AUTOSAR XML (schema 4-3-0)
standard types defined: SInt32, UInt16, UInt32, UInt8, sint32, uint16, uint32, uint8
package /DataTypes
  impl type SGaugeInfo_u32dyn_3: category=ARRAY, sw-calibration-access=READ-ONLY, type-emitter=RTE
    element Element: array-size=3, array-size-semantics=FIXED-SIZE, implementation-data-type=SGaugeInfo_u32dyn
package /E40_Platform_System_SystemPackage/Components
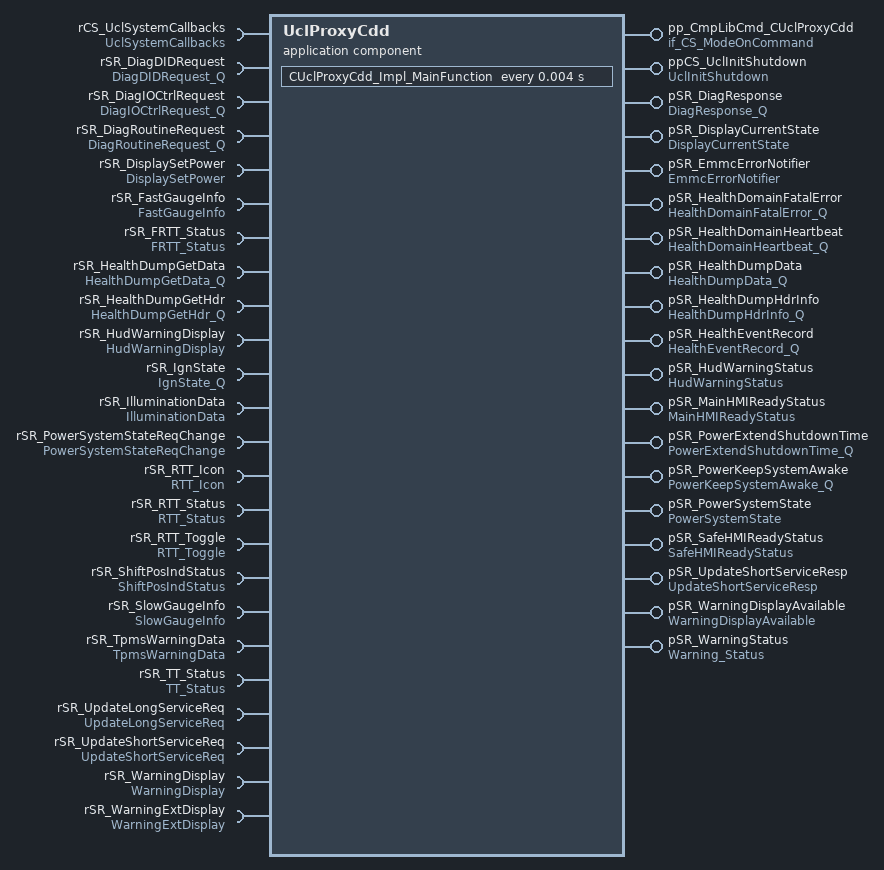
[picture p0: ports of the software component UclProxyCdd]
  application sw component type UclProxyCdd
    19 x provide port:
      pp_CmpLibCmd_CUclProxyCdd: server-com-spec{operation=Impl_OnCommand, queue-length=1}, provided-interface=if_CS_ModeOnCommand
      ppCS_UclInitShutdown: provided-com-specs=[{operation=Impl_Initialize, queue-length=1}, {operation=Impl_Shutdown, queue-length=1}], provided-interface=UclInitShutdown
      pSR_DiagResponse: queued-sender-com-spec=data-element=DiagResponseData, provided-interface=DiagResponse_Q
      pSR_DisplayCurrentState: nonqueued-sender-com-spec{data-element=DisplayCurrentStateData, init-value=constant-reference=UclProxyCddDisplayCurrentStateDataValue0}, provided-interface=DisplayCurrentState
      pSR_EmmcErrorNotifier: nonqueued-sender-com-spec{data-element=EmmcErrorNotifierData, init-value=constant-reference=UclProxyCddEmmcErrorNotifierDataValue0}, provided-interface=EmmcErrorNotifier
      pSR_HealthDomainFatalError: queued-sender-com-spec=data-element=HealthDomainFatalErrorData, provided-interface=HealthDomainFatalError_Q
      pSR_HealthDomainHeartbeat: queued-sender-com-spec=data-element=HealthDomainHeartbeatData, provided-interface=HealthDomainHeartbeat_Q
      pSR_HealthDumpData: queued-sender-com-spec=data-element=HealthDumpDataData, provided-interface=HealthDumpData_Q
      pSR_HealthDumpHdrInfo: queued-sender-com-spec=data-element=HealthDumpHdrInfoData, provided-interface=HealthDumpHdrInfo_Q
      pSR_HealthEventRecord: queued-sender-com-spec=data-element=HealthEventRecordData, provided-interface=HealthEventRecord_Q
      pSR_HudWarningStatus: nonqueued-sender-com-spec{data-element=HudWarningStatusData, init-value=constant-reference=UclProxyCddHudWarningStatusDataValue0}, provided-interface=HudWarningStatus
      pSR_MainHMIReadyStatus: queued-sender-com-spec=data-element=MainHMIReadyStatusData, provided-interface=MainHMIReadyStatus
      pSR_PowerExtendShutdownTime: queued-sender-com-spec=data-element=PowerExtendShutdownTimeData, provided-interface=PowerExtendShutdownTime_Q
      pSR_PowerKeepSystemAwake: queued-sender-com-spec=data-element=PowerKeepSystemAwakeData, provided-interface=PowerKeepSystemAwake_Q
      pSR_PowerSystemState: nonqueued-sender-com-spec{data-element=PowerSystemStateData, init-value=constant-reference=UclProxyCddPowerSystemStateDataValue0}, provided-interface=PowerSystemState
      pSR_SafeHMIReadyStatus: queued-sender-com-spec=data-element=SafeHMIReadyStatusData, provided-interface=SafeHMIReadyStatus
      pSR_UpdateShortServiceResp: queued-sender-com-spec=data-element=UpdateShortServiceRespData, provided-interface=UpdateShortServiceResp
      pSR_WarningDisplayAvailable: nonqueued-sender-com-spec{data-element=WarningDisplayAvailableData, init-value=constant-reference=UclProxyCddWarningDisplayAvailableDataValue0}, provided-interface=WarningDisplayAvailable
      pSR_WarningStatus: nonqueued-sender-com-spec{data-element=WarningStatusData, init-value=constant-reference=UclProxyCddWarningStatusDataValue0}, provided-interface=Warning_Status
    24 x require port:
      rCS_UclSystemCallbacks: required-com-specs=[ErrorNotification, LinkStatusChanged], required-interface=UclSystemCallbacks
      rSR_DiagDIDRequest: queued-receiver-com-spec{data-element=DiagDIDRequestData, queue-length=2}, required-interface=DiagDIDRequest_Q
      rSR_DiagIOCtrlRequest: queued-receiver-com-spec{data-element=DiagIOCtrlRequestData, queue-length=2}, required-interface=DiagIOCtrlRequest_Q
      rSR_DiagRoutineRequest: queued-receiver-com-spec{data-element=DiagRoutineRequestData, queue-length=2}, required-interface=DiagRoutineRequest_Q
      rSR_DisplaySetPower: nonqueued-receiver-com-spec{data-element=DisplaySetPowerData, filter=data-filter-type=ALWAYS, init-value=constant-reference=UclProxyCddDisplaySetPowerDataValue0}, required-interface=DisplaySetPower
      rSR_FastGaugeInfo: nonqueued-receiver-com-spec{data-element=FastGaugeInfoData, filter=data-filter-type=ALWAYS, init-value=constant-reference=UclProxyCddFastGaugeInfoDataValue0}, required-interface=FastGaugeInfo
      rSR_FRTT_Status: nonqueued-receiver-com-spec{data-element=FRTT_StatusData, filter=data-filter-type=ALWAYS, init-value=constant-reference=UclProxyCddFRTT_StatusDataValue0}, required-interface=FRTT_Status
      rSR_HealthDumpGetData: queued-receiver-com-spec{data-element=HealthDumpGetDataData, queue-length=1}, required-interface=HealthDumpGetData_Q
      rSR_HealthDumpGetHdr: queued-receiver-com-spec{data-element=HealthDumpGetHdrData, queue-length=1}, required-interface=HealthDumpGetHdr_Q
      rSR_HudWarningDisplay: nonqueued-receiver-com-spec{data-element=HudWarningDisplayData, filter=data-filter-type=ALWAYS, init-value=constant-reference=UclProxyCddHudWarningDisplayDataValue0}, required-interface=HudWarningDisplay
      rSR_IgnState: queued-receiver-com-spec{data-element=IgnStateData, queue-length=5}, required-interface=IgnState_Q
      rSR_IlluminationData: nonqueued-receiver-com-spec{data-element=IlluminationDataData, filter=data-filter-type=ALWAYS, init-value=constant-reference=UclProxyCddIlluminationDataDataValue0}, required-interface=IlluminationData
      rSR_PowerSystemStateReqChange: nonqueued-receiver-com-spec{data-element=PowerSystemStateReqChangeData, filter=data-filter-type=ALWAYS, init-value=constant-reference=UclProxyCddPowerSystemStateReqChangeDataValue0}, required-interface=PowerSystemStateReqChange
      rSR_RTT_Icon: nonqueued-receiver-com-spec{data-element=RTT_IconData, filter=data-filter-type=ALWAYS, init-value=constant-reference=UclProxyCddRTT_IconDataValue0}, required-interface=RTT_Icon
      rSR_RTT_Status: nonqueued-receiver-com-spec{data-element=RTT_StatusData, filter=data-filter-type=ALWAYS, init-value=constant-reference=UclProxyCddRTT_StatusDataValue0}, required-interface=RTT_Status
      rSR_RTT_Toggle: nonqueued-receiver-com-spec{data-element=RTT_ToggleData, filter=data-filter-type=ALWAYS, init-value=constant-reference=UclProxyCddRTT_ToggleDataValue0}, required-interface=RTT_Toggle
      rSR_ShiftPosIndStatus: nonqueued-receiver-com-spec{data-element=ShiftPosIndStatusData, filter=data-filter-type=ALWAYS, init-value=constant-reference=UclProxyCddShiftPosIndStatusDataValue0}, required-interface=ShiftPosIndStatus
      rSR_SlowGaugeInfo: nonqueued-receiver-com-spec{data-element=SlowGaugeInfoData, filter=data-filter-type=ALWAYS, init-value=constant-reference=UclProxyCddSlowGaugeInfoDataValue0}, required-interface=SlowGaugeInfo
      rSR_TpmsWarningData: nonqueued-receiver-com-spec{data-element=TpmsWarningDataData, filter=data-filter-type=ALWAYS, init-value=constant-reference=UclProxyCddTpmsWarningDataDataValue0}, required-interface=TpmsWarningData
      rSR_TT_Status: nonqueued-receiver-com-spec{data-element=TT_StatusData, filter=data-filter-type=ALWAYS, init-value=constant-reference=UclProxyCddTT_StatusDataValue0}, required-interface=TT_Status
      rSR_UpdateLongServiceReq: queued-receiver-com-spec{data-element=UpdateLongServiceReqData, queue-length=1}, required-interface=UpdateLongServiceReq
      rSR_UpdateShortServiceReq: queued-receiver-com-spec{data-element=UpdateShortServiceReqData, queue-length=1}, required-interface=UpdateShortServiceReq
      rSR_WarningDisplay: nonqueued-receiver-com-spec{data-element=WarningDisplayData, filter=data-filter-type=ALWAYS, init-value=constant-reference=UclProxyCddWarningDisplayDataValue0}, required-interface=WarningDisplay
      rSR_WarningExtDisplay: nonqueued-receiver-com-spec{data-element=WarningExtDisplayData, filter=data-filter-type=ALWAYS, init-value=constant-reference=UclProxyCddWarningExtDisplayDataValue0}, required-interface=WarningExtDisplay
    behavior IB_UclProxyCdd
      operation invoked event OIE_ppCS_UclInitShutdown_CUclProxyCdd_Impl_InitializeTrigByImpl_Initialize: start-on-event=CUclProxyCdd_Impl_Initialize, operation=ppCS_UclInitShutdown.Impl_Initialize
      timing event TECUclProxyCdd_Impl_MainFunction: start-on-event=CUclProxyCdd_Impl_MainFunction, period=0.004
      operation invoked event OIE_pp_CmpLibCmd_CUclProxyCdd_CUclProxyCdd_Impl_OnCommandTrigByImpl_OnCommand: start-on-event=CUclProxyCdd_Impl_OnCommand, operation=pp_CmpLibCmd_CUclProxyCdd.Impl_OnCommand
      operation invoked event OIE_ppCS_UclInitShutdown_CUclProxyCdd_Impl_ShutdownTrigByImpl_Shutdown: start-on-event=CUclProxyCdd_Impl_Shutdown, operation=ppCS_UclInitShutdown.Impl_Shutdown
      20 x data received event:
        DREOnDre_DiagDIDRequestTrigByDiagDIDRequestData: start-on-event=OnDre_DiagDIDRequest, data=rSR_DiagDIDRequest.DiagDIDRequestData
        DREOnDre_DiagIOCtrlRequestTrigByDiagIOCtrlRequestData: start-on-event=OnDre_DiagIOCtrlRequest, data=rSR_DiagIOCtrlRequest.DiagIOCtrlRequestData
        DREOnDre_DiagRoutineRequestTrigByDiagRoutineRequestData: start-on-event=OnDre_DiagRoutineRequest, data=rSR_DiagRoutineRequest.DiagRoutineRequestData
        DREOnDre_DisplaySetPowerTrigByDisplaySetPowerData: start-on-event=OnDre_DisplaySetPower, data=rSR_DisplaySetPower.DisplaySetPowerData
        DREOnDre_FastGaugeInfoTrigByFastGaugeInfoData: start-on-event=OnDre_FastGaugeInfo, data=rSR_FastGaugeInfo.FastGaugeInfoData
        DREOnDre_FRTT_StatusTrigByFRTT_StatusData: start-on-event=OnDre_FRTT_Status, data=rSR_FRTT_Status.FRTT_StatusData
        DREOnDre_HealthDumpGetDataTrigByHealthDumpGetDataData: start-on-event=OnDre_HealthDumpGetData, data=rSR_HealthDumpGetData.HealthDumpGetDataData
        DREOnDre_HealthDumpGetHdrTrigByHealthDumpGetHdrData: start-on-event=OnDre_HealthDumpGetHdr, data=rSR_HealthDumpGetHdr.HealthDumpGetHdrData
        DREOnDre_IlluminationDataTrigByIlluminationDataData: start-on-event=OnDre_IlluminationData, data=rSR_IlluminationData.IlluminationDataData
        DREOnDre_PowerSystemStateReqChangeTrigByPowerSystemStateReqChangeData: start-on-event=OnDre_PowerSystemStateReqChange, data=rSR_PowerSystemStateReqChange.PowerSystemStateReqChangeData
        DREOnDre_RTT_IconTrigByRTT_IconData: start-on-event=OnDre_RTT_Icon, data=rSR_RTT_Icon.RTT_IconData
        DREOnDre_RTT_StatusTrigByRTT_StatusData: start-on-event=OnDre_RTT_Status, data=rSR_RTT_Status.RTT_StatusData
        DREOnDre_RTT_ToggleTrigByRTT_ToggleData: start-on-event=OnDre_RTT_Toggle, data=rSR_RTT_Toggle.RTT_ToggleData
        DREOnDre_ShiftPosIndStatusTrigByShiftPosIndStatusData: start-on-event=OnDre_ShiftPosIndStatus, data=rSR_ShiftPosIndStatus.ShiftPosIndStatusData
        DREOnDre_SlowGaugeInfoTrigBySlowGaugeInfoData: start-on-event=OnDre_SlowGaugeInfo, data=rSR_SlowGaugeInfo.SlowGaugeInfoData
        DREOnDre_TT_StatusTrigByTT_StatusData: start-on-event=OnDre_TT_Status, data=rSR_TT_Status.TT_StatusData
        DREOnDre_UpdateLongServiceReqTrigByUpdateLongServiceReqData: start-on-event=OnDre_UpdateLongServiceReq, data=rSR_UpdateLongServiceReq.UpdateLongServiceReqData
        DREOnDre_UpdateShortServiceReqTrigByUpdateShortServiceReqData: start-on-event=OnDre_UpdateShortServiceReq, data=rSR_UpdateShortServiceReq.UpdateShortServiceReqData
        DREOnDre_WarningDisplayTrigByWarningDisplayData: start-on-event=OnDre_WarningDisplay, data=rSR_WarningDisplay.WarningDisplayData
        DREOnDre_WarningExtDisplayTrigByWarningExtDisplayData: start-on-event=OnDre_WarningExtDisplay, data=rSR_WarningExtDisplay.WarningExtDisplayData
      port-api-options:
        enable-take-address=false, error-handling=NO-TRANSFORMER-ERROR-HANDLING, indirect-api=false, port=pp_CmpLibCmd_CUclProxyCdd
        enable-take-address=false, error-handling=NO-TRANSFORMER-ERROR-HANDLING, indirect-api=false, port=ppCS_UclInitShutdown
        enable-take-address=false, error-handling=NO-TRANSFORMER-ERROR-HANDLING, indirect-api=false, port=pSR_DiagResponse
        enable-take-address=false, error-handling=NO-TRANSFORMER-ERROR-HANDLING, indirect-api=false, port=pSR_DisplayCurrentState
        enable-take-address=false, error-handling=NO-TRANSFORMER-ERROR-HANDLING, indirect-api=false, port=pSR_EmmcErrorNotifier
        enable-take-address=false, error-handling=NO-TRANSFORMER-ERROR-HANDLING, indirect-api=false, port=pSR_HealthDomainFatalError
        enable-take-address=false, error-handling=NO-TRANSFORMER-ERROR-HANDLING, indirect-api=false, port=pSR_HealthDomainHeartbeat
        enable-take-address=false, error-handling=NO-TRANSFORMER-ERROR-HANDLING, indirect-api=false, port=pSR_HealthDumpData
        enable-take-address=false, error-handling=NO-TRANSFORMER-ERROR-HANDLING, indirect-api=false, port=pSR_HealthDumpHdrInfo
        enable-take-address=false, error-handling=NO-TRANSFORMER-ERROR-HANDLING, indirect-api=false, port=pSR_HealthEventRecord
        enable-take-address=false, error-handling=NO-TRANSFORMER-ERROR-HANDLING, indirect-api=false, port=pSR_HudWarningStatus
        enable-take-address=false, error-handling=NO-TRANSFORMER-ERROR-HANDLING, indirect-api=false, port=pSR_MainHMIReadyStatus
        enable-take-address=false, error-handling=NO-TRANSFORMER-ERROR-HANDLING, indirect-api=false, port=pSR_PowerExtendShutdownTime
        enable-take-address=false, error-handling=NO-TRANSFORMER-ERROR-HANDLING, indirect-api=false, port=pSR_PowerKeepSystemAwake
        enable-take-address=false, error-handling=NO-TRANSFORMER-ERROR-HANDLING, indirect-api=false, port=pSR_PowerSystemState
        enable-take-address=false, error-handling=NO-TRANSFORMER-ERROR-HANDLING, indirect-api=false, port=pSR_SafeHMIReadyStatus
        enable-take-address=false, error-handling=NO-TRANSFORMER-ERROR-HANDLING, indirect-api=false, port=pSR_UpdateShortServiceResp
        enable-take-address=false, error-handling=NO-TRANSFORMER-ERROR-HANDLING, indirect-api=false, port=pSR_WarningDisplayAvailable
        enable-take-address=false, error-handling=NO-TRANSFORMER-ERROR-HANDLING, indirect-api=false, port=pSR_WarningStatus
        enable-take-address=false, error-handling=NO-TRANSFORMER-ERROR-HANDLING, indirect-api=false, port=rCS_UclSystemCallbacks
        enable-take-address=false, error-handling=NO-TRANSFORMER-ERROR-HANDLING, indirect-api=false, port=rSR_DiagDIDRequest
        enable-take-address=false, error-handling=NO-TRANSFORMER-ERROR-HANDLING, indirect-api=false, port=rSR_DiagIOCtrlRequest
        enable-take-address=false, error-handling=NO-TRANSFORMER-ERROR-HANDLING, indirect-api=false, port=rSR_DiagRoutineRequest
        enable-take-address=false, error-handling=NO-TRANSFORMER-ERROR-HANDLING, indirect-api=false, port=rSR_DisplaySetPower
        enable-take-address=false, error-handling=NO-TRANSFORMER-ERROR-HANDLING, indirect-api=false, port=rSR_FastGaugeInfo
        enable-take-address=false, error-handling=NO-TRANSFORMER-ERROR-HANDLING, indirect-api=false, port=rSR_FRTT_Status
        enable-take-address=false, error-handling=NO-TRANSFORMER-ERROR-HANDLING, indirect-api=false, port=rSR_HealthDumpGetData
        enable-take-address=false, error-handling=NO-TRANSFORMER-ERROR-HANDLING, indirect-api=false, port=rSR_HealthDumpGetHdr
        enable-take-address=false, error-handling=NO-TRANSFORMER-ERROR-HANDLING, indirect-api=false, port=rSR_HudWarningDisplay
        enable-take-address=false, error-handling=NO-TRANSFORMER-ERROR-HANDLING, indirect-api=false, port=rSR_IgnState
        enable-take-address=false, error-handling=NO-TRANSFORMER-ERROR-HANDLING, indirect-api=false, port=rSR_IlluminationData
        enable-take-address=false, error-handling=NO-TRANSFORMER-ERROR-HANDLING, indirect-api=false, port=rSR_PowerSystemStateReqChange
        enable-take-address=false, error-handling=NO-TRANSFORMER-ERROR-HANDLING, indirect-api=false, port=rSR_RTT_Icon
        enable-take-address=false, error-handling=NO-TRANSFORMER-ERROR-HANDLING, indirect-api=false, port=rSR_RTT_Status
        enable-take-address=false, error-handling=NO-TRANSFORMER-ERROR-HANDLING, indirect-api=false, port=rSR_RTT_Toggle
        enable-take-address=false, error-handling=NO-TRANSFORMER-ERROR-HANDLING, indirect-api=false, port=rSR_ShiftPosIndStatus
        enable-take-address=false, error-handling=NO-TRANSFORMER-ERROR-HANDLING, indirect-api=false, port=rSR_SlowGaugeInfo
        enable-take-address=false, error-handling=NO-TRANSFORMER-ERROR-HANDLING, indirect-api=false, port=rSR_TpmsWarningData
        enable-take-address=false, error-handling=NO-TRANSFORMER-ERROR-HANDLING, indirect-api=false, port=rSR_TT_Status
        enable-take-address=false, error-handling=NO-TRANSFORMER-ERROR-HANDLING, indirect-api=false, port=rSR_UpdateLongServiceReq
        enable-take-address=false, error-handling=NO-TRANSFORMER-ERROR-HANDLING, indirect-api=false, port=rSR_UpdateShortServiceReq
        enable-take-address=false, error-handling=NO-TRANSFORMER-ERROR-HANDLING, indirect-api=false, port=rSR_WarningDisplay
        enable-take-address=false, error-handling=NO-TRANSFORMER-ERROR-HANDLING, indirect-api=false, port=rSR_WarningExtDisplay
      24 x runnable, all with can-be-invoked-concurrently=true:
        CUclProxyCdd_Impl_Initialize
        CUclProxyCdd_Impl_MainFunction
          data-receive-point-by-arguments:
            23 x access:
              DRA_rSR_DisplaySetPower_DisplaySetPowerData: accessed-variable=rSR_DisplaySetPower.DisplaySetPowerData
              DRA_rSR_FastGaugeInfo_FastGaugeInfoData: accessed-variable=rSR_FastGaugeInfo.FastGaugeInfoData
              DRA_rSR_FRTT_Status_FRTT_StatusData: accessed-variable=rSR_FRTT_Status.FRTT_StatusData
              DRA_rSR_HudWarningDisplay_HudWarningDisplayData: accessed-variable=rSR_HudWarningDisplay.HudWarningDisplayData
              DRA_rSR_IlluminationData_IlluminationDataData: accessed-variable=rSR_IlluminationData.IlluminationDataData
              DRA_rSR_PowerSystemStateReqChange_PowerSystemStateReqChangeData: accessed-variable=rSR_PowerSystemStateReqChange.PowerSystemStateReqChangeData
              DRA_rSR_RTT_Icon_RTT_IconData: accessed-variable=rSR_RTT_Icon.RTT_IconData
              DRA_rSR_RTT_Status_RTT_StatusData: accessed-variable=rSR_RTT_Status.RTT_StatusData
              DRA_rSR_RTT_Toggle_RTT_ToggleData: accessed-variable=rSR_RTT_Toggle.RTT_ToggleData
              DRA_rSR_ShiftPosIndStatus_ShiftPosIndStatusData: accessed-variable=rSR_ShiftPosIndStatus.ShiftPosIndStatusData
              DRA_rSR_SlowGaugeInfo_SlowGaugeInfoData: accessed-variable=rSR_SlowGaugeInfo.SlowGaugeInfoData
              DRA_rSR_TpmsWarningData_TpmsWarningDataData: accessed-variable=rSR_TpmsWarningData.TpmsWarningDataData
              DRA_rSR_TT_Status_TT_StatusData: accessed-variable=rSR_TT_Status.TT_StatusData
              DRA_rSR_WarningDisplay_WarningDisplayData: accessed-variable=rSR_WarningDisplay.WarningDisplayData
              DRA_rSR_WarningExtDisplay_WarningExtDisplayData: accessed-variable=rSR_WarningExtDisplay.WarningExtDisplayData
              DRP_rSR_DiagDIDRequest_DiagDIDRequestData: accessed-variable=rSR_DiagDIDRequest.DiagDIDRequestData
              DRP_rSR_DiagIOCtrlRequest_DiagIOCtrlRequestData: accessed-variable=rSR_DiagIOCtrlRequest.DiagIOCtrlRequestData
              DRP_rSR_DiagRoutineRequest_DiagRoutineRequestData: accessed-variable=rSR_DiagRoutineRequest.DiagRoutineRequestData
              DRP_rSR_HealthDumpGetData_HealthDumpGetDataData: accessed-variable=rSR_HealthDumpGetData.HealthDumpGetDataData
              DRP_rSR_HealthDumpGetHdr_HealthDumpGetHdrData: accessed-variable=rSR_HealthDumpGetHdr.HealthDumpGetHdrData
              DRP_rSR_IgnState_IgnStateData: accessed-variable=rSR_IgnState.IgnStateData
              DRP_rSR_UpdateLongServiceReq_UpdateLongServiceReqData: accessed-variable=rSR_UpdateLongServiceReq.UpdateLongServiceReqData
              DRP_rSR_UpdateShortServiceReq_UpdateShortServiceReqData: accessed-variable=rSR_UpdateShortServiceReq.UpdateShortServiceReqData
          data-send-points:
            17 x access:
              DSP_pSR_DiagResponse_DiagResponseData: accessed-variable=pSR_DiagResponse.DiagResponseData
              DSP_pSR_HealthDomainFatalError_HealthDomainFatalErrorData: accessed-variable=pSR_HealthDomainFatalError.HealthDomainFatalErrorData
              DSP_pSR_HealthDomainHeartbeat_HealthDomainHeartbeatData: accessed-variable=pSR_HealthDomainHeartbeat.HealthDomainHeartbeatData
              DSP_pSR_HealthDumpData_HealthDumpDataData: accessed-variable=pSR_HealthDumpData.HealthDumpDataData
              DSP_pSR_HealthDumpHdrInfo_HealthDumpHdrInfoData: accessed-variable=pSR_HealthDumpHdrInfo.HealthDumpHdrInfoData
              DSP_pSR_HealthEventRecord_HealthEventRecordData: accessed-variable=pSR_HealthEventRecord.HealthEventRecordData
              DSP_pSR_MainHMIReadyStatus_MainHMIReadyStatusData: accessed-variable=pSR_MainHMIReadyStatus.MainHMIReadyStatusData
              DSP_pSR_PowerExtendShutdownTime_PowerExtendShutdownTimeData: accessed-variable=pSR_PowerExtendShutdownTime.PowerExtendShutdownTimeData
              DSP_pSR_PowerKeepSystemAwake_PowerKeepSystemAwakeData: accessed-variable=pSR_PowerKeepSystemAwake.PowerKeepSystemAwakeData
              DSP_pSR_SafeHMIReadyStatus_SafeHMIReadyStatusData: accessed-variable=pSR_SafeHMIReadyStatus.SafeHMIReadyStatusData
              DSP_pSR_UpdateShortServiceResp_UpdateShortServiceRespData: accessed-variable=pSR_UpdateShortServiceResp.UpdateShortServiceRespData
              DWA_pSR_DisplayCurrentState_DisplayCurrentStateData: accessed-variable=pSR_DisplayCurrentState.DisplayCurrentStateData
              DWA_pSR_EmmcErrorNotifier_EmmcErrorNotifierData: accessed-variable=pSR_EmmcErrorNotifier.EmmcErrorNotifierData
              DWA_pSR_HudWarningStatus_HudWarningStatusData: accessed-variable=pSR_HudWarningStatus.HudWarningStatusData
              DWA_pSR_PowerSystemState_PowerSystemStateData: accessed-variable=pSR_PowerSystemState.PowerSystemStateData
              DWA_pSR_WarningDisplayAvailable_WarningDisplayAvailableData: accessed-variable=pSR_WarningDisplayAvailable.WarningDisplayAvailableData
              DWA_pSR_WarningStatus_WarningStatusData: accessed-variable=pSR_WarningStatus.WarningStatusData
          sync call OA_rCS_UclSystemCallbacks_ErrorNotification: operation=rCS_UclSystemCallbacks.ErrorNotification, timeout=0
          sync call OA_rCS_UclSystemCallbacks_LinkStatusChanged: operation=rCS_UclSystemCallbacks.LinkStatusChanged, timeout=0
        CUclProxyCdd_Impl_OnCommand
        CUclProxyCdd_Impl_Shutdown
        OnDre_DiagDIDRequest
          data-receive-point-by-arguments:
            23 x access:
              DRA_rSR_DisplaySetPower_DisplaySetPowerData: accessed-variable=rSR_DisplaySetPower.DisplaySetPowerData
              DRA_rSR_FastGaugeInfo_FastGaugeInfoData: accessed-variable=rSR_FastGaugeInfo.FastGaugeInfoData
              DRA_rSR_FRTT_Status_FRTT_StatusData: accessed-variable=rSR_FRTT_Status.FRTT_StatusData
              DRA_rSR_HudWarningDisplay_HudWarningDisplayData: accessed-variable=rSR_HudWarningDisplay.HudWarningDisplayData
              DRA_rSR_IlluminationData_IlluminationDataData: accessed-variable=rSR_IlluminationData.IlluminationDataData
              DRA_rSR_PowerSystemStateReqChange_PowerSystemStateReqChangeData: accessed-variable=rSR_PowerSystemStateReqChange.PowerSystemStateReqChangeData
              DRA_rSR_RTT_Icon_RTT_IconData: accessed-variable=rSR_RTT_Icon.RTT_IconData
              DRA_rSR_RTT_Status_RTT_StatusData: accessed-variable=rSR_RTT_Status.RTT_StatusData
              DRA_rSR_RTT_Toggle_RTT_ToggleData: accessed-variable=rSR_RTT_Toggle.RTT_ToggleData
              DRA_rSR_ShiftPosIndStatus_ShiftPosIndStatusData: accessed-variable=rSR_ShiftPosIndStatus.ShiftPosIndStatusData
              DRA_rSR_SlowGaugeInfo_SlowGaugeInfoData: accessed-variable=rSR_SlowGaugeInfo.SlowGaugeInfoData
              DRA_rSR_TpmsWarningData_TpmsWarningDataData: accessed-variable=rSR_TpmsWarningData.TpmsWarningDataData
              DRA_rSR_TT_Status_TT_StatusData: accessed-variable=rSR_TT_Status.TT_StatusData
              DRA_rSR_WarningDisplay_WarningDisplayData: accessed-variable=rSR_WarningDisplay.WarningDisplayData
              DRA_rSR_WarningExtDisplay_WarningExtDisplayData: accessed-variable=rSR_WarningExtDisplay.WarningExtDisplayData
              DRP_rSR_DiagDIDRequest_DiagDIDRequestData: accessed-variable=rSR_DiagDIDRequest.DiagDIDRequestData
              DRP_rSR_DiagIOCtrlRequest_DiagIOCtrlRequestData: accessed-variable=rSR_DiagIOCtrlRequest.DiagIOCtrlRequestData
              DRP_rSR_DiagRoutineRequest_DiagRoutineRequestData: accessed-variable=rSR_DiagRoutineRequest.DiagRoutineRequestData
              DRP_rSR_HealthDumpGetData_HealthDumpGetDataData: accessed-variable=rSR_HealthDumpGetData.HealthDumpGetDataData
              DRP_rSR_HealthDumpGetHdr_HealthDumpGetHdrData: accessed-variable=rSR_HealthDumpGetHdr.HealthDumpGetHdrData
              DRP_rSR_IgnState_IgnStateData: accessed-variable=rSR_IgnState.IgnStateData
              DRP_rSR_UpdateLongServiceReq_UpdateLongServiceReqData: accessed-variable=rSR_UpdateLongServiceReq.UpdateLongServiceReqData
              DRP_rSR_UpdateShortServiceReq_UpdateShortServiceReqData: accessed-variable=rSR_UpdateShortServiceReq.UpdateShortServiceReqData
          data-send-points:
            17 x access:
              DSP_pSR_DiagResponse_DiagResponseData: accessed-variable=pSR_DiagResponse.DiagResponseData
              DSP_pSR_HealthDomainFatalError_HealthDomainFatalErrorData: accessed-variable=pSR_HealthDomainFatalError.HealthDomainFatalErrorData
              DSP_pSR_HealthDomainHeartbeat_HealthDomainHeartbeatData: accessed-variable=pSR_HealthDomainHeartbeat.HealthDomainHeartbeatData
              DSP_pSR_HealthDumpData_HealthDumpDataData: accessed-variable=pSR_HealthDumpData.HealthDumpDataData
              DSP_pSR_HealthDumpHdrInfo_HealthDumpHdrInfoData: accessed-variable=pSR_HealthDumpHdrInfo.HealthDumpHdrInfoData
              DSP_pSR_HealthEventRecord_HealthEventRecordData: accessed-variable=pSR_HealthEventRecord.HealthEventRecordData
              DSP_pSR_MainHMIReadyStatus_MainHMIReadyStatusData: accessed-variable=pSR_MainHMIReadyStatus.MainHMIReadyStatusData
              DSP_pSR_PowerExtendShutdownTime_PowerExtendShutdownTimeData: accessed-variable=pSR_PowerExtendShutdownTime.PowerExtendShutdownTimeData
              DSP_pSR_PowerKeepSystemAwake_PowerKeepSystemAwakeData: accessed-variable=pSR_PowerKeepSystemAwake.PowerKeepSystemAwakeData
              DSP_pSR_SafeHMIReadyStatus_SafeHMIReadyStatusData: accessed-variable=pSR_SafeHMIReadyStatus.SafeHMIReadyStatusData
              DSP_pSR_UpdateShortServiceResp_UpdateShortServiceRespData: accessed-variable=pSR_UpdateShortServiceResp.UpdateShortServiceRespData
              DWA_pSR_DisplayCurrentState_DisplayCurrentStateData: accessed-variable=pSR_DisplayCurrentState.DisplayCurrentStateData
              DWA_pSR_EmmcErrorNotifier_EmmcErrorNotifierData: accessed-variable=pSR_EmmcErrorNotifier.EmmcErrorNotifierData
              DWA_pSR_HudWarningStatus_HudWarningStatusData: accessed-variable=pSR_HudWarningStatus.HudWarningStatusData
              DWA_pSR_PowerSystemState_PowerSystemStateData: accessed-variable=pSR_PowerSystemState.PowerSystemStateData
              DWA_pSR_WarningDisplayAvailable_WarningDisplayAvailableData: accessed-variable=pSR_WarningDisplayAvailable.WarningDisplayAvailableData
              DWA_pSR_WarningStatus_WarningStatusData: accessed-variable=pSR_WarningStatus.WarningStatusData
          sync call OA_rCS_UclSystemCallbacks_ErrorNotification: operation=rCS_UclSystemCallbacks.ErrorNotification, timeout=0
          sync call OA_rCS_UclSystemCallbacks_LinkStatusChanged: operation=rCS_UclSystemCallbacks.LinkStatusChanged, timeout=0
        OnDre_DiagIOCtrlRequest
          data-receive-point-by-arguments:
            23 x access:
              DRA_rSR_DisplaySetPower_DisplaySetPowerData: accessed-variable=rSR_DisplaySetPower.DisplaySetPowerData
              DRA_rSR_FastGaugeInfo_FastGaugeInfoData: accessed-variable=rSR_FastGaugeInfo.FastGaugeInfoData
              DRA_rSR_FRTT_Status_FRTT_StatusData: accessed-variable=rSR_FRTT_Status.FRTT_StatusData
              DRA_rSR_HudWarningDisplay_HudWarningDisplayData: accessed-variable=rSR_HudWarningDisplay.HudWarningDisplayData
              DRA_rSR_IlluminationData_IlluminationDataData: accessed-variable=rSR_IlluminationData.IlluminationDataData
              DRA_rSR_PowerSystemStateReqChange_PowerSystemStateReqChangeData: accessed-variable=rSR_PowerSystemStateReqChange.PowerSystemStateReqChangeData
              DRA_rSR_RTT_Icon_RTT_IconData: accessed-variable=rSR_RTT_Icon.RTT_IconData
              DRA_rSR_RTT_Status_RTT_StatusData: accessed-variable=rSR_RTT_Status.RTT_StatusData
              DRA_rSR_RTT_Toggle_RTT_ToggleData: accessed-variable=rSR_RTT_Toggle.RTT_ToggleData
              DRA_rSR_ShiftPosIndStatus_ShiftPosIndStatusData: accessed-variable=rSR_ShiftPosIndStatus.ShiftPosIndStatusData
              DRA_rSR_SlowGaugeInfo_SlowGaugeInfoData: accessed-variable=rSR_SlowGaugeInfo.SlowGaugeInfoData
              DRA_rSR_TpmsWarningData_TpmsWarningDataData: accessed-variable=rSR_TpmsWarningData.TpmsWarningDataData
              DRA_rSR_TT_Status_TT_StatusData: accessed-variable=rSR_TT_Status.TT_StatusData
              DRA_rSR_WarningDisplay_WarningDisplayData: accessed-variable=rSR_WarningDisplay.WarningDisplayData
              DRA_rSR_WarningExtDisplay_WarningExtDisplayData: accessed-variable=rSR_WarningExtDisplay.WarningExtDisplayData
              DRP_rSR_DiagDIDRequest_DiagDIDRequestData: accessed-variable=rSR_DiagDIDRequest.DiagDIDRequestData
              DRP_rSR_DiagIOCtrlRequest_DiagIOCtrlRequestData: accessed-variable=rSR_DiagIOCtrlRequest.DiagIOCtrlRequestData
              DRP_rSR_DiagRoutineRequest_DiagRoutineRequestData: accessed-variable=rSR_DiagRoutineRequest.DiagRoutineRequestData
              DRP_rSR_HealthDumpGetData_HealthDumpGetDataData: accessed-variable=rSR_HealthDumpGetData.HealthDumpGetDataData
              DRP_rSR_HealthDumpGetHdr_HealthDumpGetHdrData: accessed-variable=rSR_HealthDumpGetHdr.HealthDumpGetHdrData
              DRP_rSR_IgnState_IgnStateData: accessed-variable=rSR_IgnState.IgnStateData
              DRP_rSR_UpdateLongServiceReq_UpdateLongServiceReqData: accessed-variable=rSR_UpdateLongServiceReq.UpdateLongServiceReqData
              DRP_rSR_UpdateShortServiceReq_UpdateShortServiceReqData: accessed-variable=rSR_UpdateShortServiceReq.UpdateShortServiceReqData
          data-send-points:
            17 x access:
              DSP_pSR_DiagResponse_DiagResponseData: accessed-variable=pSR_DiagResponse.DiagResponseData
              DSP_pSR_HealthDomainFatalError_HealthDomainFatalErrorData: accessed-variable=pSR_HealthDomainFatalError.HealthDomainFatalErrorData
              DSP_pSR_HealthDomainHeartbeat_HealthDomainHeartbeatData: accessed-variable=pSR_HealthDomainHeartbeat.HealthDomainHeartbeatData
              DSP_pSR_HealthDumpData_HealthDumpDataData: accessed-variable=pSR_HealthDumpData.HealthDumpDataData
              DSP_pSR_HealthDumpHdrInfo_HealthDumpHdrInfoData: accessed-variable=pSR_HealthDumpHdrInfo.HealthDumpHdrInfoData
              DSP_pSR_HealthEventRecord_HealthEventRecordData: accessed-variable=pSR_HealthEventRecord.HealthEventRecordData
              DSP_pSR_MainHMIReadyStatus_MainHMIReadyStatusData: accessed-variable=pSR_MainHMIReadyStatus.MainHMIReadyStatusData
              DSP_pSR_PowerExtendShutdownTime_PowerExtendShutdownTimeData: accessed-variable=pSR_PowerExtendShutdownTime.PowerExtendShutdownTimeData
              DSP_pSR_PowerKeepSystemAwake_PowerKeepSystemAwakeData: accessed-variable=pSR_PowerKeepSystemAwake.PowerKeepSystemAwakeData
              DSP_pSR_SafeHMIReadyStatus_SafeHMIReadyStatusData: accessed-variable=pSR_SafeHMIReadyStatus.SafeHMIReadyStatusData
              DSP_pSR_UpdateShortServiceResp_UpdateShortServiceRespData: accessed-variable=pSR_UpdateShortServiceResp.UpdateShortServiceRespData
              DWA_pSR_DisplayCurrentState_DisplayCurrentStateData: accessed-variable=pSR_DisplayCurrentState.DisplayCurrentStateData
              DWA_pSR_EmmcErrorNotifier_EmmcErrorNotifierData: accessed-variable=pSR_EmmcErrorNotifier.EmmcErrorNotifierData
              DWA_pSR_HudWarningStatus_HudWarningStatusData: accessed-variable=pSR_HudWarningStatus.HudWarningStatusData
              DWA_pSR_PowerSystemState_PowerSystemStateData: accessed-variable=pSR_PowerSystemState.PowerSystemStateData
              DWA_pSR_WarningDisplayAvailable_WarningDisplayAvailableData: accessed-variable=pSR_WarningDisplayAvailable.WarningDisplayAvailableData
              DWA_pSR_WarningStatus_WarningStatusData: accessed-variable=pSR_WarningStatus.WarningStatusData
          sync call OA_rCS_UclSystemCallbacks_ErrorNotification: operation=rCS_UclSystemCallbacks.ErrorNotification, timeout=0
          sync call OA_rCS_UclSystemCallbacks_LinkStatusChanged: operation=rCS_UclSystemCallbacks.LinkStatusChanged, timeout=0
        OnDre_DiagRoutineRequest
          data-receive-point-by-arguments:
            23 x access:
              DRA_rSR_DisplaySetPower_DisplaySetPowerData: accessed-variable=rSR_DisplaySetPower.DisplaySetPowerData
              DRA_rSR_FastGaugeInfo_FastGaugeInfoData: accessed-variable=rSR_FastGaugeInfo.FastGaugeInfoData
              DRA_rSR_FRTT_Status_FRTT_StatusData: accessed-variable=rSR_FRTT_Status.FRTT_StatusData
              DRA_rSR_HudWarningDisplay_HudWarningDisplayData: accessed-variable=rSR_HudWarningDisplay.HudWarningDisplayData
              DRA_rSR_IlluminationData_IlluminationDataData: accessed-variable=rSR_IlluminationData.IlluminationDataData
              DRA_rSR_PowerSystemStateReqChange_PowerSystemStateReqChangeData: accessed-variable=rSR_PowerSystemStateReqChange.PowerSystemStateReqChangeData
              DRA_rSR_RTT_Icon_RTT_IconData: accessed-variable=rSR_RTT_Icon.RTT_IconData
              DRA_rSR_RTT_Status_RTT_StatusData: accessed-variable=rSR_RTT_Status.RTT_StatusData
              DRA_rSR_RTT_Toggle_RTT_ToggleData: accessed-variable=rSR_RTT_Toggle.RTT_ToggleData
              DRA_rSR_ShiftPosIndStatus_ShiftPosIndStatusData: accessed-variable=rSR_ShiftPosIndStatus.ShiftPosIndStatusData
              DRA_rSR_SlowGaugeInfo_SlowGaugeInfoData: accessed-variable=rSR_SlowGaugeInfo.SlowGaugeInfoData
              DRA_rSR_TpmsWarningData_TpmsWarningDataData: accessed-variable=rSR_TpmsWarningData.TpmsWarningDataData
              DRA_rSR_TT_Status_TT_StatusData: accessed-variable=rSR_TT_Status.TT_StatusData
              DRA_rSR_WarningDisplay_WarningDisplayData: accessed-variable=rSR_WarningDisplay.WarningDisplayData
              DRA_rSR_WarningExtDisplay_WarningExtDisplayData: accessed-variable=rSR_WarningExtDisplay.WarningExtDisplayData
              DRP_rSR_DiagDIDRequest_DiagDIDRequestData: accessed-variable=rSR_DiagDIDRequest.DiagDIDRequestData
              DRP_rSR_DiagIOCtrlRequest_DiagIOCtrlRequestData: accessed-variable=rSR_DiagIOCtrlRequest.DiagIOCtrlRequestData
              DRP_rSR_DiagRoutineRequest_DiagRoutineRequestData: accessed-variable=rSR_DiagRoutineRequest.DiagRoutineRequestData
              DRP_rSR_HealthDumpGetData_HealthDumpGetDataData: accessed-variable=rSR_HealthDumpGetData.HealthDumpGetDataData
              DRP_rSR_HealthDumpGetHdr_HealthDumpGetHdrData: accessed-variable=rSR_HealthDumpGetHdr.HealthDumpGetHdrData
              DRP_rSR_IgnState_IgnStateData: accessed-variable=rSR_IgnState.IgnStateData
              DRP_rSR_UpdateLongServiceReq_UpdateLongServiceReqData: accessed-variable=rSR_UpdateLongServiceReq.UpdateLongServiceReqData
              DRP_rSR_UpdateShortServiceReq_UpdateShortServiceReqData: accessed-variable=rSR_UpdateShortServiceReq.UpdateShortServiceReqData
          data-send-points:
            17 x access:
              DSP_pSR_DiagResponse_DiagResponseData: accessed-variable=pSR_DiagResponse.DiagResponseData
              DSP_pSR_HealthDomainFatalError_HealthDomainFatalErrorData: accessed-variable=pSR_HealthDomainFatalError.HealthDomainFatalErrorData
              DSP_pSR_HealthDomainHeartbeat_HealthDomainHeartbeatData: accessed-variable=pSR_HealthDomainHeartbeat.HealthDomainHeartbeatData
              DSP_pSR_HealthDumpData_HealthDumpDataData: accessed-variable=pSR_HealthDumpData.HealthDumpDataData
              DSP_pSR_HealthDumpHdrInfo_HealthDumpHdrInfoData: accessed-variable=pSR_HealthDumpHdrInfo.HealthDumpHdrInfoData
              DSP_pSR_HealthEventRecord_HealthEventRecordData: accessed-variable=pSR_HealthEventRecord.HealthEventRecordData
              DSP_pSR_MainHMIReadyStatus_MainHMIReadyStatusData: accessed-variable=pSR_MainHMIReadyStatus.MainHMIReadyStatusData
              DSP_pSR_PowerExtendShutdownTime_PowerExtendShutdownTimeData: accessed-variable=pSR_PowerExtendShutdownTime.PowerExtendShutdownTimeData
              DSP_pSR_PowerKeepSystemAwake_PowerKeepSystemAwakeData: accessed-variable=pSR_PowerKeepSystemAwake.PowerKeepSystemAwakeData
              DSP_pSR_SafeHMIReadyStatus_SafeHMIReadyStatusData: accessed-variable=pSR_SafeHMIReadyStatus.SafeHMIReadyStatusData
              DSP_pSR_UpdateShortServiceResp_UpdateShortServiceRespData: accessed-variable=pSR_UpdateShortServiceResp.UpdateShortServiceRespData
              DWA_pSR_DisplayCurrentState_DisplayCurrentStateData: accessed-variable=pSR_DisplayCurrentState.DisplayCurrentStateData
              DWA_pSR_EmmcErrorNotifier_EmmcErrorNotifierData: accessed-variable=pSR_EmmcErrorNotifier.EmmcErrorNotifierData
              DWA_pSR_HudWarningStatus_HudWarningStatusData: accessed-variable=pSR_HudWarningStatus.HudWarningStatusData
              DWA_pSR_PowerSystemState_PowerSystemStateData: accessed-variable=pSR_PowerSystemState.PowerSystemStateData
              DWA_pSR_WarningDisplayAvailable_WarningDisplayAvailableData: accessed-variable=pSR_WarningDisplayAvailable.WarningDisplayAvailableData
              DWA_pSR_WarningStatus_WarningStatusData: accessed-variable=pSR_WarningStatus.WarningStatusData
          sync call OA_rCS_UclSystemCallbacks_ErrorNotification: operation=rCS_UclSystemCallbacks.ErrorNotification, timeout=0
          sync call OA_rCS_UclSystemCallbacks_LinkStatusChanged: operation=rCS_UclSystemCallbacks.LinkStatusChanged, timeout=0
        OnDre_DisplaySetPower
          data-receive-point-by-arguments:
            23 x access:
              DRA_rSR_DisplaySetPower_DisplaySetPowerData: accessed-variable=rSR_DisplaySetPower.DisplaySetPowerData
              DRA_rSR_FastGaugeInfo_FastGaugeInfoData: accessed-variable=rSR_FastGaugeInfo.FastGaugeInfoData
              DRA_rSR_FRTT_Status_FRTT_StatusData: accessed-variable=rSR_FRTT_Status.FRTT_StatusData
              DRA_rSR_HudWarningDisplay_HudWarningDisplayData: accessed-variable=rSR_HudWarningDisplay.HudWarningDisplayData
              DRA_rSR_IlluminationData_IlluminationDataData: accessed-variable=rSR_IlluminationData.IlluminationDataData
              DRA_rSR_PowerSystemStateReqChange_PowerSystemStateReqChangeData: accessed-variable=rSR_PowerSystemStateReqChange.PowerSystemStateReqChangeData
              DRA_rSR_RTT_Icon_RTT_IconData: accessed-variable=rSR_RTT_Icon.RTT_IconData
              DRA_rSR_RTT_Status_RTT_StatusData: accessed-variable=rSR_RTT_Status.RTT_StatusData
              DRA_rSR_RTT_Toggle_RTT_ToggleData: accessed-variable=rSR_RTT_Toggle.RTT_ToggleData
              DRA_rSR_ShiftPosIndStatus_ShiftPosIndStatusData: accessed-variable=rSR_ShiftPosIndStatus.ShiftPosIndStatusData
              DRA_rSR_SlowGaugeInfo_SlowGaugeInfoData: accessed-variable=rSR_SlowGaugeInfo.SlowGaugeInfoData
              DRA_rSR_TpmsWarningData_TpmsWarningDataData: accessed-variable=rSR_TpmsWarningData.TpmsWarningDataData
              DRA_rSR_TT_Status_TT_StatusData: accessed-variable=rSR_TT_Status.TT_StatusData
              DRA_rSR_WarningDisplay_WarningDisplayData: accessed-variable=rSR_WarningDisplay.WarningDisplayData
              DRA_rSR_WarningExtDisplay_WarningExtDisplayData: accessed-variable=rSR_WarningExtDisplay.WarningExtDisplayData
              DRP_rSR_DiagDIDRequest_DiagDIDRequestData: accessed-variable=rSR_DiagDIDRequest.DiagDIDRequestData
              DRP_rSR_DiagIOCtrlRequest_DiagIOCtrlRequestData: accessed-variable=rSR_DiagIOCtrlRequest.DiagIOCtrlRequestData
              DRP_rSR_DiagRoutineRequest_DiagRoutineRequestData: accessed-variable=rSR_DiagRoutineRequest.DiagRoutineRequestData
              DRP_rSR_HealthDumpGetData_HealthDumpGetDataData: accessed-variable=rSR_HealthDumpGetData.HealthDumpGetDataData
              DRP_rSR_HealthDumpGetHdr_HealthDumpGetHdrData: accessed-variable=rSR_HealthDumpGetHdr.HealthDumpGetHdrData
              DRP_rSR_IgnState_IgnStateData: accessed-variable=rSR_IgnState.IgnStateData
              DRP_rSR_UpdateLongServiceReq_UpdateLongServiceReqData: accessed-variable=rSR_UpdateLongServiceReq.UpdateLongServiceReqData
              DRP_rSR_UpdateShortServiceReq_UpdateShortServiceReqData: accessed-variable=rSR_UpdateShortServiceReq.UpdateShortServiceReqData
          data-send-points:
            17 x access:
              DSP_pSR_DiagResponse_DiagResponseData: accessed-variable=pSR_DiagResponse.DiagResponseData
              DSP_pSR_HealthDomainFatalError_HealthDomainFatalErrorData: accessed-variable=pSR_HealthDomainFatalError.HealthDomainFatalErrorData
              DSP_pSR_HealthDomainHeartbeat_HealthDomainHeartbeatData: accessed-variable=pSR_HealthDomainHeartbeat.HealthDomainHeartbeatData
              DSP_pSR_HealthDumpData_HealthDumpDataData: accessed-variable=pSR_HealthDumpData.HealthDumpDataData
              DSP_pSR_HealthDumpHdrInfo_HealthDumpHdrInfoData: accessed-variable=pSR_HealthDumpHdrInfo.HealthDumpHdrInfoData
              DSP_pSR_HealthEventRecord_HealthEventRecordData: accessed-variable=pSR_HealthEventRecord.HealthEventRecordData
              DSP_pSR_MainHMIReadyStatus_MainHMIReadyStatusData: accessed-variable=pSR_MainHMIReadyStatus.MainHMIReadyStatusData
              DSP_pSR_PowerExtendShutdownTime_PowerExtendShutdownTimeData: accessed-variable=pSR_PowerExtendShutdownTime.PowerExtendShutdownTimeData
              DSP_pSR_PowerKeepSystemAwake_PowerKeepSystemAwakeData: accessed-variable=pSR_PowerKeepSystemAwake.PowerKeepSystemAwakeData
              DSP_pSR_SafeHMIReadyStatus_SafeHMIReadyStatusData: accessed-variable=pSR_SafeHMIReadyStatus.SafeHMIReadyStatusData
              DSP_pSR_UpdateShortServiceResp_UpdateShortServiceRespData: accessed-variable=pSR_UpdateShortServiceResp.UpdateShortServiceRespData
              DWA_pSR_DisplayCurrentState_DisplayCurrentStateData: accessed-variable=pSR_DisplayCurrentState.DisplayCurrentStateData
              DWA_pSR_EmmcErrorNotifier_EmmcErrorNotifierData: accessed-variable=pSR_EmmcErrorNotifier.EmmcErrorNotifierData
              DWA_pSR_HudWarningStatus_HudWarningStatusData: accessed-variable=pSR_HudWarningStatus.HudWarningStatusData
              DWA_pSR_PowerSystemState_PowerSystemStateData: accessed-variable=pSR_PowerSystemState.PowerSystemStateData
              DWA_pSR_WarningDisplayAvailable_WarningDisplayAvailableData: accessed-variable=pSR_WarningDisplayAvailable.WarningDisplayAvailableData
              DWA_pSR_WarningStatus_WarningStatusData: accessed-variable=pSR_WarningStatus.WarningStatusData
          sync call OA_rCS_UclSystemCallbacks_ErrorNotification: operation=rCS_UclSystemCallbacks.ErrorNotification, timeout=0
          sync call OA_rCS_UclSystemCallbacks_LinkStatusChanged: operation=rCS_UclSystemCallbacks.LinkStatusChanged, timeout=0
        OnDre_FastGaugeInfo
          data-receive-point-by-arguments:
            23 x access:
              DRA_rSR_DisplaySetPower_DisplaySetPowerData: accessed-variable=rSR_DisplaySetPower.DisplaySetPowerData
              DRA_rSR_FastGaugeInfo_FastGaugeInfoData: accessed-variable=rSR_FastGaugeInfo.FastGaugeInfoData
              DRA_rSR_FRTT_Status_FRTT_StatusData: accessed-variable=rSR_FRTT_Status.FRTT_StatusData
              DRA_rSR_HudWarningDisplay_HudWarningDisplayData: accessed-variable=rSR_HudWarningDisplay.HudWarningDisplayData
              DRA_rSR_IlluminationData_IlluminationDataData: accessed-variable=rSR_IlluminationData.IlluminationDataData
              DRA_rSR_PowerSystemStateReqChange_PowerSystemStateReqChangeData: accessed-variable=rSR_PowerSystemStateReqChange.PowerSystemStateReqChangeData
              DRA_rSR_RTT_Icon_RTT_IconData: accessed-variable=rSR_RTT_Icon.RTT_IconData
              DRA_rSR_RTT_Status_RTT_StatusData: accessed-variable=rSR_RTT_Status.RTT_StatusData
              DRA_rSR_RTT_Toggle_RTT_ToggleData: accessed-variable=rSR_RTT_Toggle.RTT_ToggleData
              DRA_rSR_ShiftPosIndStatus_ShiftPosIndStatusData: accessed-variable=rSR_ShiftPosIndStatus.ShiftPosIndStatusData
              DRA_rSR_SlowGaugeInfo_SlowGaugeInfoData: accessed-variable=rSR_SlowGaugeInfo.SlowGaugeInfoData
              DRA_rSR_TpmsWarningData_TpmsWarningDataData: accessed-variable=rSR_TpmsWarningData.TpmsWarningDataData
              DRA_rSR_TT_Status_TT_StatusData: accessed-variable=rSR_TT_Status.TT_StatusData
              DRA_rSR_WarningDisplay_WarningDisplayData: accessed-variable=rSR_WarningDisplay.WarningDisplayData
              DRA_rSR_WarningExtDisplay_WarningExtDisplayData: accessed-variable=rSR_WarningExtDisplay.WarningExtDisplayData
              DRP_rSR_DiagDIDRequest_DiagDIDRequestData: accessed-variable=rSR_DiagDIDRequest.DiagDIDRequestData
              DRP_rSR_DiagIOCtrlRequest_DiagIOCtrlRequestData: accessed-variable=rSR_DiagIOCtrlRequest.DiagIOCtrlRequestData
              DRP_rSR_DiagRoutineRequest_DiagRoutineRequestData: accessed-variable=rSR_DiagRoutineRequest.DiagRoutineRequestData
              DRP_rSR_HealthDumpGetData_HealthDumpGetDataData: accessed-variable=rSR_HealthDumpGetData.HealthDumpGetDataData
              DRP_rSR_HealthDumpGetHdr_HealthDumpGetHdrData: accessed-variable=rSR_HealthDumpGetHdr.HealthDumpGetHdrData
              DRP_rSR_IgnState_IgnStateData: accessed-variable=rSR_IgnState.IgnStateData
              DRP_rSR_UpdateLongServiceReq_UpdateLongServiceReqData: accessed-variable=rSR_UpdateLongServiceReq.UpdateLongServiceReqData
              DRP_rSR_UpdateShortServiceReq_UpdateShortServiceReqData: accessed-variable=rSR_UpdateShortServiceReq.UpdateShortServiceReqData
          data-send-points:
            17 x access:
              DSP_pSR_DiagResponse_DiagResponseData: accessed-variable=pSR_DiagResponse.DiagResponseData
              DSP_pSR_HealthDomainFatalError_HealthDomainFatalErrorData: accessed-variable=pSR_HealthDomainFatalError.HealthDomainFatalErrorData
              DSP_pSR_HealthDomainHeartbeat_HealthDomainHeartbeatData: accessed-variable=pSR_HealthDomainHeartbeat.HealthDomainHeartbeatData
              DSP_pSR_HealthDumpData_HealthDumpDataData: accessed-variable=pSR_HealthDumpData.HealthDumpDataData
              DSP_pSR_HealthDumpHdrInfo_HealthDumpHdrInfoData: accessed-variable=pSR_HealthDumpHdrInfo.HealthDumpHdrInfoData
              DSP_pSR_HealthEventRecord_HealthEventRecordData: accessed-variable=pSR_HealthEventRecord.HealthEventRecordData
              DSP_pSR_MainHMIReadyStatus_MainHMIReadyStatusData: accessed-variable=pSR_MainHMIReadyStatus.MainHMIReadyStatusData
              DSP_pSR_PowerExtendShutdownTime_PowerExtendShutdownTimeData: accessed-variable=pSR_PowerExtendShutdownTime.PowerExtendShutdownTimeData
              DSP_pSR_PowerKeepSystemAwake_PowerKeepSystemAwakeData: accessed-variable=pSR_PowerKeepSystemAwake.PowerKeepSystemAwakeData
              DSP_pSR_SafeHMIReadyStatus_SafeHMIReadyStatusData: accessed-variable=pSR_SafeHMIReadyStatus.SafeHMIReadyStatusData
              DSP_pSR_UpdateShortServiceResp_UpdateShortServiceRespData: accessed-variable=pSR_UpdateShortServiceResp.UpdateShortServiceRespData
              DWA_pSR_DisplayCurrentState_DisplayCurrentStateData: accessed-variable=pSR_DisplayCurrentState.DisplayCurrentStateData
              DWA_pSR_EmmcErrorNotifier_EmmcErrorNotifierData: accessed-variable=pSR_EmmcErrorNotifier.EmmcErrorNotifierData
              DWA_pSR_HudWarningStatus_HudWarningStatusData: accessed-variable=pSR_HudWarningStatus.HudWarningStatusData
              DWA_pSR_PowerSystemState_PowerSystemStateData: accessed-variable=pSR_PowerSystemState.PowerSystemStateData
              DWA_pSR_WarningDisplayAvailable_WarningDisplayAvailableData: accessed-variable=pSR_WarningDisplayAvailable.WarningDisplayAvailableData
              DWA_pSR_WarningStatus_WarningStatusData: accessed-variable=pSR_WarningStatus.WarningStatusData
          sync call OA_rCS_UclSystemCallbacks_ErrorNotification: operation=rCS_UclSystemCallbacks.ErrorNotification, timeout=0
          sync call OA_rCS_UclSystemCallbacks_LinkStatusChanged: operation=rCS_UclSystemCallbacks.LinkStatusChanged, timeout=0
        OnDre_FRTT_Status
          data-receive-point-by-arguments:
            23 x access:
              DRA_rSR_DisplaySetPower_DisplaySetPowerData: accessed-variable=rSR_DisplaySetPower.DisplaySetPowerData
              DRA_rSR_FastGaugeInfo_FastGaugeInfoData: accessed-variable=rSR_FastGaugeInfo.FastGaugeInfoData
              DRA_rSR_FRTT_Status_FRTT_StatusData: accessed-variable=rSR_FRTT_Status.FRTT_StatusData
              DRA_rSR_HudWarningDisplay_HudWarningDisplayData: accessed-variable=rSR_HudWarningDisplay.HudWarningDisplayData
              DRA_rSR_IlluminationData_IlluminationDataData: accessed-variable=rSR_IlluminationData.IlluminationDataData
              DRA_rSR_PowerSystemStateReqChange_PowerSystemStateReqChangeData: accessed-variable=rSR_PowerSystemStateReqChange.PowerSystemStateReqChangeData
              DRA_rSR_RTT_Icon_RTT_IconData: accessed-variable=rSR_RTT_Icon.RTT_IconData
              DRA_rSR_RTT_Status_RTT_StatusData: accessed-variable=rSR_RTT_Status.RTT_StatusData
              DRA_rSR_RTT_Toggle_RTT_ToggleData: accessed-variable=rSR_RTT_Toggle.RTT_ToggleData
              DRA_rSR_ShiftPosIndStatus_ShiftPosIndStatusData: accessed-variable=rSR_ShiftPosIndStatus.ShiftPosIndStatusData
              DRA_rSR_SlowGaugeInfo_SlowGaugeInfoData: accessed-variable=rSR_SlowGaugeInfo.SlowGaugeInfoData
              DRA_rSR_TpmsWarningData_TpmsWarningDataData: accessed-variable=rSR_TpmsWarningData.TpmsWarningDataData
              DRA_rSR_TT_Status_TT_StatusData: accessed-variable=rSR_TT_Status.TT_StatusData
              DRA_rSR_WarningDisplay_WarningDisplayData: accessed-variable=rSR_WarningDisplay.WarningDisplayData
              DRA_rSR_WarningExtDisplay_WarningExtDisplayData: accessed-variable=rSR_WarningExtDisplay.WarningExtDisplayData
              DRP_rSR_DiagDIDRequest_DiagDIDRequestData: accessed-variable=rSR_DiagDIDRequest.DiagDIDRequestData
              DRP_rSR_DiagIOCtrlRequest_DiagIOCtrlRequestData: accessed-variable=rSR_DiagIOCtrlRequest.DiagIOCtrlRequestData
              DRP_rSR_DiagRoutineRequest_DiagRoutineRequestData: accessed-variable=rSR_DiagRoutineRequest.DiagRoutineRequestData
              DRP_rSR_HealthDumpGetData_HealthDumpGetDataData: accessed-variable=rSR_HealthDumpGetData.HealthDumpGetDataData
              DRP_rSR_HealthDumpGetHdr_HealthDumpGetHdrData: accessed-variable=rSR_HealthDumpGetHdr.HealthDumpGetHdrData
              DRP_rSR_IgnState_IgnStateData: accessed-variable=rSR_IgnState.IgnStateData
              DRP_rSR_UpdateLongServiceReq_UpdateLongServiceReqData: accessed-variable=rSR_UpdateLongServiceReq.UpdateLongServiceReqData
              DRP_rSR_UpdateShortServiceReq_UpdateShortServiceReqData: accessed-variable=rSR_UpdateShortServiceReq.UpdateShortServiceReqData
          data-send-points:
            17 x access:
              DSP_pSR_DiagResponse_DiagResponseData: accessed-variable=pSR_DiagResponse.DiagResponseData
              DSP_pSR_HealthDomainFatalError_HealthDomainFatalErrorData: accessed-variable=pSR_HealthDomainFatalError.HealthDomainFatalErrorData
              DSP_pSR_HealthDomainHeartbeat_HealthDomainHeartbeatData: accessed-variable=pSR_HealthDomainHeartbeat.HealthDomainHeartbeatData
              DSP_pSR_HealthDumpData_HealthDumpDataData: accessed-variable=pSR_HealthDumpData.HealthDumpDataData
              DSP_pSR_HealthDumpHdrInfo_HealthDumpHdrInfoData: accessed-variable=pSR_HealthDumpHdrInfo.HealthDumpHdrInfoData
              DSP_pSR_HealthEventRecord_HealthEventRecordData: accessed-variable=pSR_HealthEventRecord.HealthEventRecordData
              DSP_pSR_MainHMIReadyStatus_MainHMIReadyStatusData: accessed-variable=pSR_MainHMIReadyStatus.MainHMIReadyStatusData
              DSP_pSR_PowerExtendShutdownTime_PowerExtendShutdownTimeData: accessed-variable=pSR_PowerExtendShutdownTime.PowerExtendShutdownTimeData
              DSP_pSR_PowerKeepSystemAwake_PowerKeepSystemAwakeData: accessed-variable=pSR_PowerKeepSystemAwake.PowerKeepSystemAwakeData
              DSP_pSR_SafeHMIReadyStatus_SafeHMIReadyStatusData: accessed-variable=pSR_SafeHMIReadyStatus.SafeHMIReadyStatusData
              DSP_pSR_UpdateShortServiceResp_UpdateShortServiceRespData: accessed-variable=pSR_UpdateShortServiceResp.UpdateShortServiceRespData
              DWA_pSR_DisplayCurrentState_DisplayCurrentStateData: accessed-variable=pSR_DisplayCurrentState.DisplayCurrentStateData
              DWA_pSR_EmmcErrorNotifier_EmmcErrorNotifierData: accessed-variable=pSR_EmmcErrorNotifier.EmmcErrorNotifierData
              DWA_pSR_HudWarningStatus_HudWarningStatusData: accessed-variable=pSR_HudWarningStatus.HudWarningStatusData
              DWA_pSR_PowerSystemState_PowerSystemStateData: accessed-variable=pSR_PowerSystemState.PowerSystemStateData
              DWA_pSR_WarningDisplayAvailable_WarningDisplayAvailableData: accessed-variable=pSR_WarningDisplayAvailable.WarningDisplayAvailableData
              DWA_pSR_WarningStatus_WarningStatusData: accessed-variable=pSR_WarningStatus.WarningStatusData
          sync call OA_rCS_UclSystemCallbacks_ErrorNotification: operation=rCS_UclSystemCallbacks.ErrorNotification, timeout=0
          sync call OA_rCS_UclSystemCallbacks_LinkStatusChanged: operation=rCS_UclSystemCallbacks.LinkStatusChanged, timeout=0
        OnDre_HealthDumpGetData
          data-receive-point-by-arguments:
            23 x access:
              DRA_rSR_DisplaySetPower_DisplaySetPowerData: accessed-variable=rSR_DisplaySetPower.DisplaySetPowerData
              DRA_rSR_FastGaugeInfo_FastGaugeInfoData: accessed-variable=rSR_FastGaugeInfo.FastGaugeInfoData
              DRA_rSR_FRTT_Status_FRTT_StatusData: accessed-variable=rSR_FRTT_Status.FRTT_StatusData
              DRA_rSR_HudWarningDisplay_HudWarningDisplayData: accessed-variable=rSR_HudWarningDisplay.HudWarningDisplayData
              DRA_rSR_IlluminationData_IlluminationDataData: accessed-variable=rSR_IlluminationData.IlluminationDataData
              DRA_rSR_PowerSystemStateReqChange_PowerSystemStateReqChangeData: accessed-variable=rSR_PowerSystemStateReqChange.PowerSystemStateReqChangeData
              DRA_rSR_RTT_Icon_RTT_IconData: accessed-variable=rSR_RTT_Icon.RTT_IconData
              DRA_rSR_RTT_Status_RTT_StatusData: accessed-variable=rSR_RTT_Status.RTT_StatusData
              DRA_rSR_RTT_Toggle_RTT_ToggleData: accessed-variable=rSR_RTT_Toggle.RTT_ToggleData
              DRA_rSR_ShiftPosIndStatus_ShiftPosIndStatusData: accessed-variable=rSR_ShiftPosIndStatus.ShiftPosIndStatusData
              DRA_rSR_SlowGaugeInfo_SlowGaugeInfoData: accessed-variable=rSR_SlowGaugeInfo.SlowGaugeInfoData
              DRA_rSR_TpmsWarningData_TpmsWarningDataData: accessed-variable=rSR_TpmsWarningData.TpmsWarningDataData
              DRA_rSR_TT_Status_TT_StatusData: accessed-variable=rSR_TT_Status.TT_StatusData
              DRA_rSR_WarningDisplay_WarningDisplayData: accessed-variable=rSR_WarningDisplay.WarningDisplayData
              DRA_rSR_WarningExtDisplay_WarningExtDisplayData: accessed-variable=rSR_WarningExtDisplay.WarningExtDisplayData
              DRP_rSR_DiagDIDRequest_DiagDIDRequestData: accessed-variable=rSR_DiagDIDRequest.DiagDIDRequestData
              DRP_rSR_DiagIOCtrlRequest_DiagIOCtrlRequestData: accessed-variable=rSR_DiagIOCtrlRequest.DiagIOCtrlRequestData
              DRP_rSR_DiagRoutineRequest_DiagRoutineRequestData: accessed-variable=rSR_DiagRoutineRequest.DiagRoutineRequestData
              DRP_rSR_HealthDumpGetData_HealthDumpGetDataData: accessed-variable=rSR_HealthDumpGetData.HealthDumpGetDataData
              DRP_rSR_HealthDumpGetHdr_HealthDumpGetHdrData: accessed-variable=rSR_HealthDumpGetHdr.HealthDumpGetHdrData
              DRP_rSR_IgnState_IgnStateData: accessed-variable=rSR_IgnState.IgnStateData
              DRP_rSR_UpdateLongServiceReq_UpdateLongServiceReqData: accessed-variable=rSR_UpdateLongServiceReq.UpdateLongServiceReqData
              DRP_rSR_UpdateShortServiceReq_UpdateShortServiceReqData: accessed-variable=rSR_UpdateShortServiceReq.UpdateShortServiceReqData
          data-send-points:
            17 x access:
              DSP_pSR_DiagResponse_DiagResponseData: accessed-variable=pSR_DiagResponse.DiagResponseData
              DSP_pSR_HealthDomainFatalError_HealthDomainFatalErrorData: accessed-variable=pSR_HealthDomainFatalError.HealthDomainFatalErrorData
              DSP_pSR_HealthDomainHeartbeat_HealthDomainHeartbeatData: accessed-variable=pSR_HealthDomainHeartbeat.HealthDomainHeartbeatData
              DSP_pSR_HealthDumpData_HealthDumpDataData: accessed-variable=pSR_HealthDumpData.HealthDumpDataData
              DSP_pSR_HealthDumpHdrInfo_HealthDumpHdrInfoData: accessed-variable=pSR_HealthDumpHdrInfo.HealthDumpHdrInfoData
              DSP_pSR_HealthEventRecord_HealthEventRecordData: accessed-variable=pSR_HealthEventRecord.HealthEventRecordData
              DSP_pSR_MainHMIReadyStatus_MainHMIReadyStatusData: accessed-variable=pSR_MainHMIReadyStatus.MainHMIReadyStatusData
              DSP_pSR_PowerExtendShutdownTime_PowerExtendShutdownTimeData: accessed-variable=pSR_PowerExtendShutdownTime.PowerExtendShutdownTimeData
              DSP_pSR_PowerKeepSystemAwake_PowerKeepSystemAwakeData: accessed-variable=pSR_PowerKeepSystemAwake.PowerKeepSystemAwakeData
              DSP_pSR_SafeHMIReadyStatus_SafeHMIReadyStatusData: accessed-variable=pSR_SafeHMIReadyStatus.SafeHMIReadyStatusData
              DSP_pSR_UpdateShortServiceResp_UpdateShortServiceRespData: accessed-variable=pSR_UpdateShortServiceResp.UpdateShortServiceRespData
              DWA_pSR_DisplayCurrentState_DisplayCurrentStateData: accessed-variable=pSR_DisplayCurrentState.DisplayCurrentStateData
              DWA_pSR_EmmcErrorNotifier_EmmcErrorNotifierData: accessed-variable=pSR_EmmcErrorNotifier.EmmcErrorNotifierData
              DWA_pSR_HudWarningStatus_HudWarningStatusData: accessed-variable=pSR_HudWarningStatus.HudWarningStatusData
              DWA_pSR_PowerSystemState_PowerSystemStateData: accessed-variable=pSR_PowerSystemState.PowerSystemStateData
              DWA_pSR_WarningDisplayAvailable_WarningDisplayAvailableData: accessed-variable=pSR_WarningDisplayAvailable.WarningDisplayAvailableData
              DWA_pSR_WarningStatus_WarningStatusData: accessed-variable=pSR_WarningStatus.WarningStatusData
          sync call OA_rCS_UclSystemCallbacks_ErrorNotification: operation=rCS_UclSystemCallbacks.ErrorNotification, timeout=0
          sync call OA_rCS_UclSystemCallbacks_LinkStatusChanged: operation=rCS_UclSystemCallbacks.LinkStatusChanged, timeout=0
        OnDre_HealthDumpGetHdr
          data-receive-point-by-arguments:
            23 x access:
              DRA_rSR_DisplaySetPower_DisplaySetPowerData: accessed-variable=rSR_DisplaySetPower.DisplaySetPowerData
              DRA_rSR_FastGaugeInfo_FastGaugeInfoData: accessed-variable=rSR_FastGaugeInfo.FastGaugeInfoData
              DRA_rSR_FRTT_Status_FRTT_StatusData: accessed-variable=rSR_FRTT_Status.FRTT_StatusData
              DRA_rSR_HudWarningDisplay_HudWarningDisplayData: accessed-variable=rSR_HudWarningDisplay.HudWarningDisplayData
              DRA_rSR_IlluminationData_IlluminationDataData: accessed-variable=rSR_IlluminationData.IlluminationDataData
              DRA_rSR_PowerSystemStateReqChange_PowerSystemStateReqChangeData: accessed-variable=rSR_PowerSystemStateReqChange.PowerSystemStateReqChangeData
              DRA_rSR_RTT_Icon_RTT_IconData: accessed-variable=rSR_RTT_Icon.RTT_IconData
              DRA_rSR_RTT_Status_RTT_StatusData: accessed-variable=rSR_RTT_Status.RTT_StatusData
              DRA_rSR_RTT_Toggle_RTT_ToggleData: accessed-variable=rSR_RTT_Toggle.RTT_ToggleData
              DRA_rSR_ShiftPosIndStatus_ShiftPosIndStatusData: accessed-variable=rSR_ShiftPosIndStatus.ShiftPosIndStatusData
              DRA_rSR_SlowGaugeInfo_SlowGaugeInfoData: accessed-variable=rSR_SlowGaugeInfo.SlowGaugeInfoData
              DRA_rSR_TpmsWarningData_TpmsWarningDataData: accessed-variable=rSR_TpmsWarningData.TpmsWarningDataData
              DRA_rSR_TT_Status_TT_StatusData: accessed-variable=rSR_TT_Status.TT_StatusData
              DRA_rSR_WarningDisplay_WarningDisplayData: accessed-variable=rSR_WarningDisplay.WarningDisplayData
              DRA_rSR_WarningExtDisplay_WarningExtDisplayData: accessed-variable=rSR_WarningExtDisplay.WarningExtDisplayData
              DRP_rSR_DiagDIDRequest_DiagDIDRequestData: accessed-variable=rSR_DiagDIDRequest.DiagDIDRequestData
              DRP_rSR_DiagIOCtrlRequest_DiagIOCtrlRequestData: accessed-variable=rSR_DiagIOCtrlRequest.DiagIOCtrlRequestData
              DRP_rSR_DiagRoutineRequest_DiagRoutineRequestData: accessed-variable=rSR_DiagRoutineRequest.DiagRoutineRequestData
              DRP_rSR_HealthDumpGetData_HealthDumpGetDataData: accessed-variable=rSR_HealthDumpGetData.HealthDumpGetDataData
              DRP_rSR_HealthDumpGetHdr_HealthDumpGetHdrData: accessed-variable=rSR_HealthDumpGetHdr.HealthDumpGetHdrData
              DRP_rSR_IgnState_IgnStateData: accessed-variable=rSR_IgnState.IgnStateData
              DRP_rSR_UpdateLongServiceReq_UpdateLongServiceReqData: accessed-variable=rSR_UpdateLongServiceReq.UpdateLongServiceReqData
              DRP_rSR_UpdateShortServiceReq_UpdateShortServiceReqData: accessed-variable=rSR_UpdateShortServiceReq.UpdateShortServiceReqData
          data-send-points:
            17 x access:
              DSP_pSR_DiagResponse_DiagResponseData: accessed-variable=pSR_DiagResponse.DiagResponseData
              DSP_pSR_HealthDomainFatalError_HealthDomainFatalErrorData: accessed-variable=pSR_HealthDomainFatalError.HealthDomainFatalErrorData
              DSP_pSR_HealthDomainHeartbeat_HealthDomainHeartbeatData: accessed-variable=pSR_HealthDomainHeartbeat.HealthDomainHeartbeatData
              DSP_pSR_HealthDumpData_HealthDumpDataData: accessed-variable=pSR_HealthDumpData.HealthDumpDataData
              DSP_pSR_HealthDumpHdrInfo_HealthDumpHdrInfoData: accessed-variable=pSR_HealthDumpHdrInfo.HealthDumpHdrInfoData
              DSP_pSR_HealthEventRecord_HealthEventRecordData: accessed-variable=pSR_HealthEventRecord.HealthEventRecordData
              DSP_pSR_MainHMIReadyStatus_MainHMIReadyStatusData: accessed-variable=pSR_MainHMIReadyStatus.MainHMIReadyStatusData
              DSP_pSR_PowerExtendShutdownTime_PowerExtendShutdownTimeData: accessed-variable=pSR_PowerExtendShutdownTime.PowerExtendShutdownTimeData
              DSP_pSR_PowerKeepSystemAwake_PowerKeepSystemAwakeData: accessed-variable=pSR_PowerKeepSystemAwake.PowerKeepSystemAwakeData
              DSP_pSR_SafeHMIReadyStatus_SafeHMIReadyStatusData: accessed-variable=pSR_SafeHMIReadyStatus.SafeHMIReadyStatusData
              DSP_pSR_UpdateShortServiceResp_UpdateShortServiceRespData: accessed-variable=pSR_UpdateShortServiceResp.UpdateShortServiceRespData
              DWA_pSR_DisplayCurrentState_DisplayCurrentStateData: accessed-variable=pSR_DisplayCurrentState.DisplayCurrentStateData
              DWA_pSR_EmmcErrorNotifier_EmmcErrorNotifierData: accessed-variable=pSR_EmmcErrorNotifier.EmmcErrorNotifierData
              DWA_pSR_HudWarningStatus_HudWarningStatusData: accessed-variable=pSR_HudWarningStatus.HudWarningStatusData
              DWA_pSR_PowerSystemState_PowerSystemStateData: accessed-variable=pSR_PowerSystemState.PowerSystemStateData
              DWA_pSR_WarningDisplayAvailable_WarningDisplayAvailableData: accessed-variable=pSR_WarningDisplayAvailable.WarningDisplayAvailableData
              DWA_pSR_WarningStatus_WarningStatusData: accessed-variable=pSR_WarningStatus.WarningStatusData
          sync call OA_rCS_UclSystemCallbacks_ErrorNotification: operation=rCS_UclSystemCallbacks.ErrorNotification, timeout=0
          sync call OA_rCS_UclSystemCallbacks_LinkStatusChanged: operation=rCS_UclSystemCallbacks.LinkStatusChanged, timeout=0
        OnDre_IlluminationData
          data-receive-point-by-arguments:
            23 x access:
              DRA_rSR_DisplaySetPower_DisplaySetPowerData: accessed-variable=rSR_DisplaySetPower.DisplaySetPowerData
              DRA_rSR_FastGaugeInfo_FastGaugeInfoData: accessed-variable=rSR_FastGaugeInfo.FastGaugeInfoData
              DRA_rSR_FRTT_Status_FRTT_StatusData: accessed-variable=rSR_FRTT_Status.FRTT_StatusData
              DRA_rSR_HudWarningDisplay_HudWarningDisplayData: accessed-variable=rSR_HudWarningDisplay.HudWarningDisplayData
              DRA_rSR_IlluminationData_IlluminationDataData: accessed-variable=rSR_IlluminationData.IlluminationDataData
              DRA_rSR_PowerSystemStateReqChange_PowerSystemStateReqChangeData: accessed-variable=rSR_PowerSystemStateReqChange.PowerSystemStateReqChangeData
              DRA_rSR_RTT_Icon_RTT_IconData: accessed-variable=rSR_RTT_Icon.RTT_IconData
              DRA_rSR_RTT_Status_RTT_StatusData: accessed-variable=rSR_RTT_Status.RTT_StatusData
              DRA_rSR_RTT_Toggle_RTT_ToggleData: accessed-variable=rSR_RTT_Toggle.RTT_ToggleData
              DRA_rSR_ShiftPosIndStatus_ShiftPosIndStatusData: accessed-variable=rSR_ShiftPosIndStatus.ShiftPosIndStatusData
              DRA_rSR_SlowGaugeInfo_SlowGaugeInfoData: accessed-variable=rSR_SlowGaugeInfo.SlowGaugeInfoData
              DRA_rSR_TpmsWarningData_TpmsWarningDataData: accessed-variable=rSR_TpmsWarningData.TpmsWarningDataData
              DRA_rSR_TT_Status_TT_StatusData: accessed-variable=rSR_TT_Status.TT_StatusData
              DRA_rSR_WarningDisplay_WarningDisplayData: accessed-variable=rSR_WarningDisplay.WarningDisplayData
              DRA_rSR_WarningExtDisplay_WarningExtDisplayData: accessed-variable=rSR_WarningExtDisplay.WarningExtDisplayData
              DRP_rSR_DiagDIDRequest_DiagDIDRequestData: accessed-variable=rSR_DiagDIDRequest.DiagDIDRequestData
              DRP_rSR_DiagIOCtrlRequest_DiagIOCtrlRequestData: accessed-variable=rSR_DiagIOCtrlRequest.DiagIOCtrlRequestData
              DRP_rSR_DiagRoutineRequest_DiagRoutineRequestData: accessed-variable=rSR_DiagRoutineRequest.DiagRoutineRequestData
              DRP_rSR_HealthDumpGetData_HealthDumpGetDataData: accessed-variable=rSR_HealthDumpGetData.HealthDumpGetDataData
              DRP_rSR_HealthDumpGetHdr_HealthDumpGetHdrData: accessed-variable=rSR_HealthDumpGetHdr.HealthDumpGetHdrData
              DRP_rSR_IgnState_IgnStateData: accessed-variable=rSR_IgnState.IgnStateData
              DRP_rSR_UpdateLongServiceReq_UpdateLongServiceReqData: accessed-variable=rSR_UpdateLongServiceReq.UpdateLongServiceReqData
              DRP_rSR_UpdateShortServiceReq_UpdateShortServiceReqData: accessed-variable=rSR_UpdateShortServiceReq.UpdateShortServiceReqData
          data-send-points:
            17 x access:
              DSP_pSR_DiagResponse_DiagResponseData: accessed-variable=pSR_DiagResponse.DiagResponseData
              DSP_pSR_HealthDomainFatalError_HealthDomainFatalErrorData: accessed-variable=pSR_HealthDomainFatalError.HealthDomainFatalErrorData
              DSP_pSR_HealthDomainHeartbeat_HealthDomainHeartbeatData: accessed-variable=pSR_HealthDomainHeartbeat.HealthDomainHeartbeatData
              DSP_pSR_HealthDumpData_HealthDumpDataData: accessed-variable=pSR_HealthDumpData.HealthDumpDataData
              DSP_pSR_HealthDumpHdrInfo_HealthDumpHdrInfoData: accessed-variable=pSR_HealthDumpHdrInfo.HealthDumpHdrInfoData
              DSP_pSR_HealthEventRecord_HealthEventRecordData: accessed-variable=pSR_HealthEventRecord.HealthEventRecordData
              DSP_pSR_MainHMIReadyStatus_MainHMIReadyStatusData: accessed-variable=pSR_MainHMIReadyStatus.MainHMIReadyStatusData
              DSP_pSR_PowerExtendShutdownTime_PowerExtendShutdownTimeData: accessed-variable=pSR_PowerExtendShutdownTime.PowerExtendShutdownTimeData
              DSP_pSR_PowerKeepSystemAwake_PowerKeepSystemAwakeData: accessed-variable=pSR_PowerKeepSystemAwake.PowerKeepSystemAwakeData
              DSP_pSR_SafeHMIReadyStatus_SafeHMIReadyStatusData: accessed-variable=pSR_SafeHMIReadyStatus.SafeHMIReadyStatusData
              DSP_pSR_UpdateShortServiceResp_UpdateShortServiceRespData: accessed-variable=pSR_UpdateShortServiceResp.UpdateShortServiceRespData
              DWA_pSR_DisplayCurrentState_DisplayCurrentStateData: accessed-variable=pSR_DisplayCurrentState.DisplayCurrentStateData
              DWA_pSR_EmmcErrorNotifier_EmmcErrorNotifierData: accessed-variable=pSR_EmmcErrorNotifier.EmmcErrorNotifierData
              DWA_pSR_HudWarningStatus_HudWarningStatusData: accessed-variable=pSR_HudWarningStatus.HudWarningStatusData
              DWA_pSR_PowerSystemState_PowerSystemStateData: accessed-variable=pSR_PowerSystemState.PowerSystemStateData
              DWA_pSR_WarningDisplayAvailable_WarningDisplayAvailableData: accessed-variable=pSR_WarningDisplayAvailable.WarningDisplayAvailableData
              DWA_pSR_WarningStatus_WarningStatusData: accessed-variable=pSR_WarningStatus.WarningStatusData
          sync call OA_rCS_UclSystemCallbacks_ErrorNotification: operation=rCS_UclSystemCallbacks.ErrorNotification, timeout=0
          sync call OA_rCS_UclSystemCallbacks_LinkStatusChanged: operation=rCS_UclSystemCallbacks.LinkStatusChanged, timeout=0
        OnDre_PowerSystemStateReqChange
          data-receive-point-by-arguments:
            23 x access:
              DRA_rSR_DisplaySetPower_DisplaySetPowerData: accessed-variable=rSR_DisplaySetPower.DisplaySetPowerData
              DRA_rSR_FastGaugeInfo_FastGaugeInfoData: accessed-variable=rSR_FastGaugeInfo.FastGaugeInfoData
              DRA_rSR_FRTT_Status_FRTT_StatusData: accessed-variable=rSR_FRTT_Status.FRTT_StatusData
              DRA_rSR_HudWarningDisplay_HudWarningDisplayData: accessed-variable=rSR_HudWarningDisplay.HudWarningDisplayData
              DRA_rSR_IlluminationData_IlluminationDataData: accessed-variable=rSR_IlluminationData.IlluminationDataData
              DRA_rSR_PowerSystemStateReqChange_PowerSystemStateReqChangeData: accessed-variable=rSR_PowerSystemStateReqChange.PowerSystemStateReqChangeData
              DRA_rSR_RTT_Icon_RTT_IconData: accessed-variable=rSR_RTT_Icon.RTT_IconData
              DRA_rSR_RTT_Status_RTT_StatusData: accessed-variable=rSR_RTT_Status.RTT_StatusData
              DRA_rSR_RTT_Toggle_RTT_ToggleData: accessed-variable=rSR_RTT_Toggle.RTT_ToggleData
              DRA_rSR_ShiftPosIndStatus_ShiftPosIndStatusData: accessed-variable=rSR_ShiftPosIndStatus.ShiftPosIndStatusData
              DRA_rSR_SlowGaugeInfo_SlowGaugeInfoData: accessed-variable=rSR_SlowGaugeInfo.SlowGaugeInfoData
              DRA_rSR_TpmsWarningData_TpmsWarningDataData: accessed-variable=rSR_TpmsWarningData.TpmsWarningDataData
              DRA_rSR_TT_Status_TT_StatusData: accessed-variable=rSR_TT_Status.TT_StatusData
              DRA_rSR_WarningDisplay_WarningDisplayData: accessed-variable=rSR_WarningDisplay.WarningDisplayData
              DRA_rSR_WarningExtDisplay_WarningExtDisplayData: accessed-variable=rSR_WarningExtDisplay.WarningExtDisplayData
              DRP_rSR_DiagDIDRequest_DiagDIDRequestData: accessed-variable=rSR_DiagDIDRequest.DiagDIDRequestData
              DRP_rSR_DiagIOCtrlRequest_DiagIOCtrlRequestData: accessed-variable=rSR_DiagIOCtrlRequest.DiagIOCtrlRequestData
              DRP_rSR_DiagRoutineRequest_DiagRoutineRequestData: accessed-variable=rSR_DiagRoutineRequest.DiagRoutineRequestData
              DRP_rSR_HealthDumpGetData_HealthDumpGetDataData: accessed-variable=rSR_HealthDumpGetData.HealthDumpGetDataData
              DRP_rSR_HealthDumpGetHdr_HealthDumpGetHdrData: accessed-variable=rSR_HealthDumpGetHdr.HealthDumpGetHdrData
              DRP_rSR_IgnState_IgnStateData: accessed-variable=rSR_IgnState.IgnStateData
              DRP_rSR_UpdateLongServiceReq_UpdateLongServiceReqData: accessed-variable=rSR_UpdateLongServiceReq.UpdateLongServiceReqData
              DRP_rSR_UpdateShortServiceReq_UpdateShortServiceReqData: accessed-variable=rSR_UpdateShortServiceReq.UpdateShortServiceReqData
          data-send-points:
            17 x access:
              DSP_pSR_DiagResponse_DiagResponseData: accessed-variable=pSR_DiagResponse.DiagResponseData
              DSP_pSR_HealthDomainFatalError_HealthDomainFatalErrorData: accessed-variable=pSR_HealthDomainFatalError.HealthDomainFatalErrorData
              DSP_pSR_HealthDomainHeartbeat_HealthDomainHeartbeatData: accessed-variable=pSR_HealthDomainHeartbeat.HealthDomainHeartbeatData
              DSP_pSR_HealthDumpData_HealthDumpDataData: accessed-variable=pSR_HealthDumpData.HealthDumpDataData
              DSP_pSR_HealthDumpHdrInfo_HealthDumpHdrInfoData: accessed-variable=pSR_HealthDumpHdrInfo.HealthDumpHdrInfoData
              DSP_pSR_HealthEventRecord_HealthEventRecordData: accessed-variable=pSR_HealthEventRecord.HealthEventRecordData
              DSP_pSR_MainHMIReadyStatus_MainHMIReadyStatusData: accessed-variable=pSR_MainHMIReadyStatus.MainHMIReadyStatusData
              DSP_pSR_PowerExtendShutdownTime_PowerExtendShutdownTimeData: accessed-variable=pSR_PowerExtendShutdownTime.PowerExtendShutdownTimeData
              DSP_pSR_PowerKeepSystemAwake_PowerKeepSystemAwakeData: accessed-variable=pSR_PowerKeepSystemAwake.PowerKeepSystemAwakeData
              DSP_pSR_SafeHMIReadyStatus_SafeHMIReadyStatusData: accessed-variable=pSR_SafeHMIReadyStatus.SafeHMIReadyStatusData
              DSP_pSR_UpdateShortServiceResp_UpdateShortServiceRespData: accessed-variable=pSR_UpdateShortServiceResp.UpdateShortServiceRespData
              DWA_pSR_DisplayCurrentState_DisplayCurrentStateData: accessed-variable=pSR_DisplayCurrentState.DisplayCurrentStateData
              DWA_pSR_EmmcErrorNotifier_EmmcErrorNotifierData: accessed-variable=pSR_EmmcErrorNotifier.EmmcErrorNotifierData
              DWA_pSR_HudWarningStatus_HudWarningStatusData: accessed-variable=pSR_HudWarningStatus.HudWarningStatusData
              DWA_pSR_PowerSystemState_PowerSystemStateData: accessed-variable=pSR_PowerSystemState.PowerSystemStateData
              DWA_pSR_WarningDisplayAvailable_WarningDisplayAvailableData: accessed-variable=pSR_WarningDisplayAvailable.WarningDisplayAvailableData
              DWA_pSR_WarningStatus_WarningStatusData: accessed-variable=pSR_WarningStatus.WarningStatusData
          sync call OA_rCS_UclSystemCallbacks_ErrorNotification: operation=rCS_UclSystemCallbacks.ErrorNotification, timeout=0
          sync call OA_rCS_UclSystemCallbacks_LinkStatusChanged: operation=rCS_UclSystemCallbacks.LinkStatusChanged, timeout=0
        OnDre_RTT_Icon
          data-receive-point-by-arguments:
            23 x access:
              DRA_rSR_DisplaySetPower_DisplaySetPowerData: accessed-variable=rSR_DisplaySetPower.DisplaySetPowerData
              DRA_rSR_FastGaugeInfo_FastGaugeInfoData: accessed-variable=rSR_FastGaugeInfo.FastGaugeInfoData
              DRA_rSR_FRTT_Status_FRTT_StatusData: accessed-variable=rSR_FRTT_Status.FRTT_StatusData
              DRA_rSR_HudWarningDisplay_HudWarningDisplayData: accessed-variable=rSR_HudWarningDisplay.HudWarningDisplayData
              DRA_rSR_IlluminationData_IlluminationDataData: accessed-variable=rSR_IlluminationData.IlluminationDataData
              DRA_rSR_PowerSystemStateReqChange_PowerSystemStateReqChangeData: accessed-variable=rSR_PowerSystemStateReqChange.PowerSystemStateReqChangeData
              DRA_rSR_RTT_Icon_RTT_IconData: accessed-variable=rSR_RTT_Icon.RTT_IconData
              DRA_rSR_RTT_Status_RTT_StatusData: accessed-variable=rSR_RTT_Status.RTT_StatusData
              DRA_rSR_RTT_Toggle_RTT_ToggleData: accessed-variable=rSR_RTT_Toggle.RTT_ToggleData
              DRA_rSR_ShiftPosIndStatus_ShiftPosIndStatusData: accessed-variable=rSR_ShiftPosIndStatus.ShiftPosIndStatusData
              DRA_rSR_SlowGaugeInfo_SlowGaugeInfoData: accessed-variable=rSR_SlowGaugeInfo.SlowGaugeInfoData
              DRA_rSR_TpmsWarningData_TpmsWarningDataData: accessed-variable=rSR_TpmsWarningData.TpmsWarningDataData
              DRA_rSR_TT_Status_TT_StatusData: accessed-variable=rSR_TT_Status.TT_StatusData
              DRA_rSR_WarningDisplay_WarningDisplayData: accessed-variable=rSR_WarningDisplay.WarningDisplayData
              DRA_rSR_WarningExtDisplay_WarningExtDisplayData: accessed-variable=rSR_WarningExtDisplay.WarningExtDisplayData
              DRP_rSR_DiagDIDRequest_DiagDIDRequestData: accessed-variable=rSR_DiagDIDRequest.DiagDIDRequestData
              DRP_rSR_DiagIOCtrlRequest_DiagIOCtrlRequestData: accessed-variable=rSR_DiagIOCtrlRequest.DiagIOCtrlRequestData
              DRP_rSR_DiagRoutineRequest_DiagRoutineRequestData: accessed-variable=rSR_DiagRoutineRequest.DiagRoutineRequestData
              DRP_rSR_HealthDumpGetData_HealthDumpGetDataData: accessed-variable=rSR_HealthDumpGetData.HealthDumpGetDataData
              DRP_rSR_HealthDumpGetHdr_HealthDumpGetHdrData: accessed-variable=rSR_HealthDumpGetHdr.HealthDumpGetHdrData
              DRP_rSR_IgnState_IgnStateData: accessed-variable=rSR_IgnState.IgnStateData
              DRP_rSR_UpdateLongServiceReq_UpdateLongServiceReqData: accessed-variable=rSR_UpdateLongServiceReq.UpdateLongServiceReqData
              DRP_rSR_UpdateShortServiceReq_UpdateShortServiceReqData: accessed-variable=rSR_UpdateShortServiceReq.UpdateShortServiceReqData
          data-send-points:
            17 x access:
              DSP_pSR_DiagResponse_DiagResponseData: accessed-variable=pSR_DiagResponse.DiagResponseData
              DSP_pSR_HealthDomainFatalError_HealthDomainFatalErrorData: accessed-variable=pSR_HealthDomainFatalError.HealthDomainFatalErrorData
              DSP_pSR_HealthDomainHeartbeat_HealthDomainHeartbeatData: accessed-variable=pSR_HealthDomainHeartbeat.HealthDomainHeartbeatData
              DSP_pSR_HealthDumpData_HealthDumpDataData: accessed-variable=pSR_HealthDumpData.HealthDumpDataData
              DSP_pSR_HealthDumpHdrInfo_HealthDumpHdrInfoData: accessed-variable=pSR_HealthDumpHdrInfo.HealthDumpHdrInfoData
              DSP_pSR_HealthEventRecord_HealthEventRecordData: accessed-variable=pSR_HealthEventRecord.HealthEventRecordData
              DSP_pSR_MainHMIReadyStatus_MainHMIReadyStatusData: accessed-variable=pSR_MainHMIReadyStatus.MainHMIReadyStatusData
              DSP_pSR_PowerExtendShutdownTime_PowerExtendShutdownTimeData: accessed-variable=pSR_PowerExtendShutdownTime.PowerExtendShutdownTimeData
              DSP_pSR_PowerKeepSystemAwake_PowerKeepSystemAwakeData: accessed-variable=pSR_PowerKeepSystemAwake.PowerKeepSystemAwakeData
              DSP_pSR_SafeHMIReadyStatus_SafeHMIReadyStatusData: accessed-variable=pSR_SafeHMIReadyStatus.SafeHMIReadyStatusData
              DSP_pSR_UpdateShortServiceResp_UpdateShortServiceRespData: accessed-variable=pSR_UpdateShortServiceResp.UpdateShortServiceRespData
              DWA_pSR_DisplayCurrentState_DisplayCurrentStateData: accessed-variable=pSR_DisplayCurrentState.DisplayCurrentStateData
              DWA_pSR_EmmcErrorNotifier_EmmcErrorNotifierData: accessed-variable=pSR_EmmcErrorNotifier.EmmcErrorNotifierData
              DWA_pSR_HudWarningStatus_HudWarningStatusData: accessed-variable=pSR_HudWarningStatus.HudWarningStatusData
              DWA_pSR_PowerSystemState_PowerSystemStateData: accessed-variable=pSR_PowerSystemState.PowerSystemStateData
              DWA_pSR_WarningDisplayAvailable_WarningDisplayAvailableData: accessed-variable=pSR_WarningDisplayAvailable.WarningDisplayAvailableData
              DWA_pSR_WarningStatus_WarningStatusData: accessed-variable=pSR_WarningStatus.WarningStatusData
          sync call OA_rCS_UclSystemCallbacks_ErrorNotification: operation=rCS_UclSystemCallbacks.ErrorNotification, timeout=0
          sync call OA_rCS_UclSystemCallbacks_LinkStatusChanged: operation=rCS_UclSystemCallbacks.LinkStatusChanged, timeout=0
        OnDre_RTT_Status
          data-receive-point-by-arguments:
            23 x access:
              DRA_rSR_DisplaySetPower_DisplaySetPowerData: accessed-variable=rSR_DisplaySetPower.DisplaySetPowerData
              DRA_rSR_FastGaugeInfo_FastGaugeInfoData: accessed-variable=rSR_FastGaugeInfo.FastGaugeInfoData
              DRA_rSR_FRTT_Status_FRTT_StatusData: accessed-variable=rSR_FRTT_Status.FRTT_StatusData
              DRA_rSR_HudWarningDisplay_HudWarningDisplayData: accessed-variable=rSR_HudWarningDisplay.HudWarningDisplayData
              DRA_rSR_IlluminationData_IlluminationDataData: accessed-variable=rSR_IlluminationData.IlluminationDataData
              DRA_rSR_PowerSystemStateReqChange_PowerSystemStateReqChangeData: accessed-variable=rSR_PowerSystemStateReqChange.PowerSystemStateReqChangeData
              DRA_rSR_RTT_Icon_RTT_IconData: accessed-variable=rSR_RTT_Icon.RTT_IconData
              DRA_rSR_RTT_Status_RTT_StatusData: accessed-variable=rSR_RTT_Status.RTT_StatusData
              DRA_rSR_RTT_Toggle_RTT_ToggleData: accessed-variable=rSR_RTT_Toggle.RTT_ToggleData
              DRA_rSR_ShiftPosIndStatus_ShiftPosIndStatusData: accessed-variable=rSR_ShiftPosIndStatus.ShiftPosIndStatusData
              DRA_rSR_SlowGaugeInfo_SlowGaugeInfoData: accessed-variable=rSR_SlowGaugeInfo.SlowGaugeInfoData
              DRA_rSR_TpmsWarningData_TpmsWarningDataData: accessed-variable=rSR_TpmsWarningData.TpmsWarningDataData
              DRA_rSR_TT_Status_TT_StatusData: accessed-variable=rSR_TT_Status.TT_StatusData
              DRA_rSR_WarningDisplay_WarningDisplayData: accessed-variable=rSR_WarningDisplay.WarningDisplayData
              DRA_rSR_WarningExtDisplay_WarningExtDisplayData: accessed-variable=rSR_WarningExtDisplay.WarningExtDisplayData
              DRP_rSR_DiagDIDRequest_DiagDIDRequestData: accessed-variable=rSR_DiagDIDRequest.DiagDIDRequestData
              DRP_rSR_DiagIOCtrlRequest_DiagIOCtrlRequestData: accessed-variable=rSR_DiagIOCtrlRequest.DiagIOCtrlRequestData
              DRP_rSR_DiagRoutineRequest_DiagRoutineRequestData: accessed-variable=rSR_DiagRoutineRequest.DiagRoutineRequestData
              DRP_rSR_HealthDumpGetData_HealthDumpGetDataData: accessed-variable=rSR_HealthDumpGetData.HealthDumpGetDataData
              DRP_rSR_HealthDumpGetHdr_HealthDumpGetHdrData: accessed-variable=rSR_HealthDumpGetHdr.HealthDumpGetHdrData
              DRP_rSR_IgnState_IgnStateData: accessed-variable=rSR_IgnState.IgnStateData
              DRP_rSR_UpdateLongServiceReq_UpdateLongServiceReqData: accessed-variable=rSR_UpdateLongServiceReq.UpdateLongServiceReqData
              DRP_rSR_UpdateShortServiceReq_UpdateShortServiceReqData: accessed-variable=rSR_UpdateShortServiceReq.UpdateShortServiceReqData
          data-send-points:
            17 x access:
              DSP_pSR_DiagResponse_DiagResponseData: accessed-variable=pSR_DiagResponse.DiagResponseData
              DSP_pSR_HealthDomainFatalError_HealthDomainFatalErrorData: accessed-variable=pSR_HealthDomainFatalError.HealthDomainFatalErrorData
              DSP_pSR_HealthDomainHeartbeat_HealthDomainHeartbeatData: accessed-variable=pSR_HealthDomainHeartbeat.HealthDomainHeartbeatData
              DSP_pSR_HealthDumpData_HealthDumpDataData: accessed-variable=pSR_HealthDumpData.HealthDumpDataData
              DSP_pSR_HealthDumpHdrInfo_HealthDumpHdrInfoData: accessed-variable=pSR_HealthDumpHdrInfo.HealthDumpHdrInfoData
              DSP_pSR_HealthEventRecord_HealthEventRecordData: accessed-variable=pSR_HealthEventRecord.HealthEventRecordData
              DSP_pSR_MainHMIReadyStatus_MainHMIReadyStatusData: accessed-variable=pSR_MainHMIReadyStatus.MainHMIReadyStatusData
              DSP_pSR_PowerExtendShutdownTime_PowerExtendShutdownTimeData: accessed-variable=pSR_PowerExtendShutdownTime.PowerExtendShutdownTimeData
              DSP_pSR_PowerKeepSystemAwake_PowerKeepSystemAwakeData: accessed-variable=pSR_PowerKeepSystemAwake.PowerKeepSystemAwakeData
              DSP_pSR_SafeHMIReadyStatus_SafeHMIReadyStatusData: accessed-variable=pSR_SafeHMIReadyStatus.SafeHMIReadyStatusData
              DSP_pSR_UpdateShortServiceResp_UpdateShortServiceRespData: accessed-variable=pSR_UpdateShortServiceResp.UpdateShortServiceRespData
              DWA_pSR_DisplayCurrentState_DisplayCurrentStateData: accessed-variable=pSR_DisplayCurrentState.DisplayCurrentStateData
              DWA_pSR_EmmcErrorNotifier_EmmcErrorNotifierData: accessed-variable=pSR_EmmcErrorNotifier.EmmcErrorNotifierData
              DWA_pSR_HudWarningStatus_HudWarningStatusData: accessed-variable=pSR_HudWarningStatus.HudWarningStatusData
              DWA_pSR_PowerSystemState_PowerSystemStateData: accessed-variable=pSR_PowerSystemState.PowerSystemStateData
              DWA_pSR_WarningDisplayAvailable_WarningDisplayAvailableData: accessed-variable=pSR_WarningDisplayAvailable.WarningDisplayAvailableData
              DWA_pSR_WarningStatus_WarningStatusData: accessed-variable=pSR_WarningStatus.WarningStatusData
          sync call OA_rCS_UclSystemCallbacks_ErrorNotification: operation=rCS_UclSystemCallbacks.ErrorNotification, timeout=0
          sync call OA_rCS_UclSystemCallbacks_LinkStatusChanged: operation=rCS_UclSystemCallbacks.LinkStatusChanged, timeout=0
        OnDre_RTT_Toggle
          data-receive-point-by-arguments:
            23 x access:
              DRA_rSR_DisplaySetPower_DisplaySetPowerData: accessed-variable=rSR_DisplaySetPower.DisplaySetPowerData
              DRA_rSR_FastGaugeInfo_FastGaugeInfoData: accessed-variable=rSR_FastGaugeInfo.FastGaugeInfoData
              DRA_rSR_FRTT_Status_FRTT_StatusData: accessed-variable=rSR_FRTT_Status.FRTT_StatusData
              DRA_rSR_HudWarningDisplay_HudWarningDisplayData: accessed-variable=rSR_HudWarningDisplay.HudWarningDisplayData
              DRA_rSR_IlluminationData_IlluminationDataData: accessed-variable=rSR_IlluminationData.IlluminationDataData
              DRA_rSR_PowerSystemStateReqChange_PowerSystemStateReqChangeData: accessed-variable=rSR_PowerSystemStateReqChange.PowerSystemStateReqChangeData
              DRA_rSR_RTT_Icon_RTT_IconData: accessed-variable=rSR_RTT_Icon.RTT_IconData
              DRA_rSR_RTT_Status_RTT_StatusData: accessed-variable=rSR_RTT_Status.RTT_StatusData
              DRA_rSR_RTT_Toggle_RTT_ToggleData: accessed-variable=rSR_RTT_Toggle.RTT_ToggleData
              DRA_rSR_ShiftPosIndStatus_ShiftPosIndStatusData: accessed-variable=rSR_ShiftPosIndStatus.ShiftPosIndStatusData
              DRA_rSR_SlowGaugeInfo_SlowGaugeInfoData: accessed-variable=rSR_SlowGaugeInfo.SlowGaugeInfoData
              DRA_rSR_TpmsWarningData_TpmsWarningDataData: accessed-variable=rSR_TpmsWarningData.TpmsWarningDataData
              DRA_rSR_TT_Status_TT_StatusData: accessed-variable=rSR_TT_Status.TT_StatusData
              DRA_rSR_WarningDisplay_WarningDisplayData: accessed-variable=rSR_WarningDisplay.WarningDisplayData
              DRA_rSR_WarningExtDisplay_WarningExtDisplayData: accessed-variable=rSR_WarningExtDisplay.WarningExtDisplayData
              DRP_rSR_DiagDIDRequest_DiagDIDRequestData: accessed-variable=rSR_DiagDIDRequest.DiagDIDRequestData
              DRP_rSR_DiagIOCtrlRequest_DiagIOCtrlRequestData: accessed-variable=rSR_DiagIOCtrlRequest.DiagIOCtrlRequestData
              DRP_rSR_DiagRoutineRequest_DiagRoutineRequestData: accessed-variable=rSR_DiagRoutineRequest.DiagRoutineRequestData
              DRP_rSR_HealthDumpGetData_HealthDumpGetDataData: accessed-variable=rSR_HealthDumpGetData.HealthDumpGetDataData
              DRP_rSR_HealthDumpGetHdr_HealthDumpGetHdrData: accessed-variable=rSR_HealthDumpGetHdr.HealthDumpGetHdrData
              DRP_rSR_IgnState_IgnStateData: accessed-variable=rSR_IgnState.IgnStateData
              DRP_rSR_UpdateLongServiceReq_UpdateLongServiceReqData: accessed-variable=rSR_UpdateLongServiceReq.UpdateLongServiceReqData
              DRP_rSR_UpdateShortServiceReq_UpdateShortServiceReqData: accessed-variable=rSR_UpdateShortServiceReq.UpdateShortServiceReqData
          data-send-points:
            17 x access:
              DSP_pSR_DiagResponse_DiagResponseData: accessed-variable=pSR_DiagResponse.DiagResponseData
              DSP_pSR_HealthDomainFatalError_HealthDomainFatalErrorData: accessed-variable=pSR_HealthDomainFatalError.HealthDomainFatalErrorData
              DSP_pSR_HealthDomainHeartbeat_HealthDomainHeartbeatData: accessed-variable=pSR_HealthDomainHeartbeat.HealthDomainHeartbeatData
              DSP_pSR_HealthDumpData_HealthDumpDataData: accessed-variable=pSR_HealthDumpData.HealthDumpDataData
              DSP_pSR_HealthDumpHdrInfo_HealthDumpHdrInfoData: accessed-variable=pSR_HealthDumpHdrInfo.HealthDumpHdrInfoData
              DSP_pSR_HealthEventRecord_HealthEventRecordData: accessed-variable=pSR_HealthEventRecord.HealthEventRecordData
              DSP_pSR_MainHMIReadyStatus_MainHMIReadyStatusData: accessed-variable=pSR_MainHMIReadyStatus.MainHMIReadyStatusData
              DSP_pSR_PowerExtendShutdownTime_PowerExtendShutdownTimeData: accessed-variable=pSR_PowerExtendShutdownTime.PowerExtendShutdownTimeData
              DSP_pSR_PowerKeepSystemAwake_PowerKeepSystemAwakeData: accessed-variable=pSR_PowerKeepSystemAwake.PowerKeepSystemAwakeData
              DSP_pSR_SafeHMIReadyStatus_SafeHMIReadyStatusData: accessed-variable=pSR_SafeHMIReadyStatus.SafeHMIReadyStatusData
              DSP_pSR_UpdateShortServiceResp_UpdateShortServiceRespData: accessed-variable=pSR_UpdateShortServiceResp.UpdateShortServiceRespData
              DWA_pSR_DisplayCurrentState_DisplayCurrentStateData: accessed-variable=pSR_DisplayCurrentState.DisplayCurrentStateData
              DWA_pSR_EmmcErrorNotifier_EmmcErrorNotifierData: accessed-variable=pSR_EmmcErrorNotifier.EmmcErrorNotifierData
              DWA_pSR_HudWarningStatus_HudWarningStatusData: accessed-variable=pSR_HudWarningStatus.HudWarningStatusData
              DWA_pSR_PowerSystemState_PowerSystemStateData: accessed-variable=pSR_PowerSystemState.PowerSystemStateData
              DWA_pSR_WarningDisplayAvailable_WarningDisplayAvailableData: accessed-variable=pSR_WarningDisplayAvailable.WarningDisplayAvailableData
              DWA_pSR_WarningStatus_WarningStatusData: accessed-variable=pSR_WarningStatus.WarningStatusData
          sync call OA_rCS_UclSystemCallbacks_ErrorNotification: operation=rCS_UclSystemCallbacks.ErrorNotification, timeout=0
          sync call OA_rCS_UclSystemCallbacks_LinkStatusChanged: operation=rCS_UclSystemCallbacks.LinkStatusChanged, timeout=0
        OnDre_ShiftPosIndStatus
          data-receive-point-by-arguments:
            23 x access:
              DRA_rSR_DisplaySetPower_DisplaySetPowerData: accessed-variable=rSR_DisplaySetPower.DisplaySetPowerData
              DRA_rSR_FastGaugeInfo_FastGaugeInfoData: accessed-variable=rSR_FastGaugeInfo.FastGaugeInfoData
              DRA_rSR_FRTT_Status_FRTT_StatusData: accessed-variable=rSR_FRTT_Status.FRTT_StatusData
              DRA_rSR_HudWarningDisplay_HudWarningDisplayData: accessed-variable=rSR_HudWarningDisplay.HudWarningDisplayData
              DRA_rSR_IlluminationData_IlluminationDataData: accessed-variable=rSR_IlluminationData.IlluminationDataData
              DRA_rSR_PowerSystemStateReqChange_PowerSystemStateReqChangeData: accessed-variable=rSR_PowerSystemStateReqChange.PowerSystemStateReqChangeData
              DRA_rSR_RTT_Icon_RTT_IconData: accessed-variable=rSR_RTT_Icon.RTT_IconData
              DRA_rSR_RTT_Status_RTT_StatusData: accessed-variable=rSR_RTT_Status.RTT_StatusData
              DRA_rSR_RTT_Toggle_RTT_ToggleData: accessed-variable=rSR_RTT_Toggle.RTT_ToggleData
              DRA_rSR_ShiftPosIndStatus_ShiftPosIndStatusData: accessed-variable=rSR_ShiftPosIndStatus.ShiftPosIndStatusData
              DRA_rSR_SlowGaugeInfo_SlowGaugeInfoData: accessed-variable=rSR_SlowGaugeInfo.SlowGaugeInfoData
              DRA_rSR_TpmsWarningData_TpmsWarningDataData: accessed-variable=rSR_TpmsWarningData.TpmsWarningDataData
              DRA_rSR_TT_Status_TT_StatusData: accessed-variable=rSR_TT_Status.TT_StatusData
              DRA_rSR_WarningDisplay_WarningDisplayData: accessed-variable=rSR_WarningDisplay.WarningDisplayData
              DRA_rSR_WarningExtDisplay_WarningExtDisplayData: accessed-variable=rSR_WarningExtDisplay.WarningExtDisplayData
              DRP_rSR_DiagDIDRequest_DiagDIDRequestData: accessed-variable=rSR_DiagDIDRequest.DiagDIDRequestData
              DRP_rSR_DiagIOCtrlRequest_DiagIOCtrlRequestData: accessed-variable=rSR_DiagIOCtrlRequest.DiagIOCtrlRequestData
              DRP_rSR_DiagRoutineRequest_DiagRoutineRequestData: accessed-variable=rSR_DiagRoutineRequest.DiagRoutineRequestData
              DRP_rSR_HealthDumpGetData_HealthDumpGetDataData: accessed-variable=rSR_HealthDumpGetData.HealthDumpGetDataData
              DRP_rSR_HealthDumpGetHdr_HealthDumpGetHdrData: accessed-variable=rSR_HealthDumpGetHdr.HealthDumpGetHdrData
              DRP_rSR_IgnState_IgnStateData: accessed-variable=rSR_IgnState.IgnStateData
              DRP_rSR_UpdateLongServiceReq_UpdateLongServiceReqData: accessed-variable=rSR_UpdateLongServiceReq.UpdateLongServiceReqData
              DRP_rSR_UpdateShortServiceReq_UpdateShortServiceReqData: accessed-variable=rSR_UpdateShortServiceReq.UpdateShortServiceReqData
          data-send-points:
            17 x access:
              DSP_pSR_DiagResponse_DiagResponseData: accessed-variable=pSR_DiagResponse.DiagResponseData
              DSP_pSR_HealthDomainFatalError_HealthDomainFatalErrorData: accessed-variable=pSR_HealthDomainFatalError.HealthDomainFatalErrorData
              DSP_pSR_HealthDomainHeartbeat_HealthDomainHeartbeatData: accessed-variable=pSR_HealthDomainHeartbeat.HealthDomainHeartbeatData
              DSP_pSR_HealthDumpData_HealthDumpDataData: accessed-variable=pSR_HealthDumpData.HealthDumpDataData
              DSP_pSR_HealthDumpHdrInfo_HealthDumpHdrInfoData: accessed-variable=pSR_HealthDumpHdrInfo.HealthDumpHdrInfoData
              DSP_pSR_HealthEventRecord_HealthEventRecordData: accessed-variable=pSR_HealthEventRecord.HealthEventRecordData
              DSP_pSR_MainHMIReadyStatus_MainHMIReadyStatusData: accessed-variable=pSR_MainHMIReadyStatus.MainHMIReadyStatusData
              DSP_pSR_PowerExtendShutdownTime_PowerExtendShutdownTimeData: accessed-variable=pSR_PowerExtendShutdownTime.PowerExtendShutdownTimeData
              DSP_pSR_PowerKeepSystemAwake_PowerKeepSystemAwakeData: accessed-variable=pSR_PowerKeepSystemAwake.PowerKeepSystemAwakeData
              DSP_pSR_SafeHMIReadyStatus_SafeHMIReadyStatusData: accessed-variable=pSR_SafeHMIReadyStatus.SafeHMIReadyStatusData
              DSP_pSR_UpdateShortServiceResp_UpdateShortServiceRespData: accessed-variable=pSR_UpdateShortServiceResp.UpdateShortServiceRespData
              DWA_pSR_DisplayCurrentState_DisplayCurrentStateData: accessed-variable=pSR_DisplayCurrentState.DisplayCurrentStateData
              DWA_pSR_EmmcErrorNotifier_EmmcErrorNotifierData: accessed-variable=pSR_EmmcErrorNotifier.EmmcErrorNotifierData
              DWA_pSR_HudWarningStatus_HudWarningStatusData: accessed-variable=pSR_HudWarningStatus.HudWarningStatusData
              DWA_pSR_PowerSystemState_PowerSystemStateData: accessed-variable=pSR_PowerSystemState.PowerSystemStateData
              DWA_pSR_WarningDisplayAvailable_WarningDisplayAvailableData: accessed-variable=pSR_WarningDisplayAvailable.WarningDisplayAvailableData
              DWA_pSR_WarningStatus_WarningStatusData: accessed-variable=pSR_WarningStatus.WarningStatusData
          sync call OA_rCS_UclSystemCallbacks_ErrorNotification: operation=rCS_UclSystemCallbacks.ErrorNotification, timeout=0
          sync call OA_rCS_UclSystemCallbacks_LinkStatusChanged: operation=rCS_UclSystemCallbacks.LinkStatusChanged, timeout=0
        OnDre_SlowGaugeInfo
          data-receive-point-by-arguments:
            23 x access:
              DRA_rSR_DisplaySetPower_DisplaySetPowerData: accessed-variable=rSR_DisplaySetPower.DisplaySetPowerData
              DRA_rSR_FastGaugeInfo_FastGaugeInfoData: accessed-variable=rSR_FastGaugeInfo.FastGaugeInfoData
              DRA_rSR_FRTT_Status_FRTT_StatusData: accessed-variable=rSR_FRTT_Status.FRTT_StatusData
              DRA_rSR_HudWarningDisplay_HudWarningDisplayData: accessed-variable=rSR_HudWarningDisplay.HudWarningDisplayData
              DRA_rSR_IlluminationData_IlluminationDataData: accessed-variable=rSR_IlluminationData.IlluminationDataData
              DRA_rSR_PowerSystemStateReqChange_PowerSystemStateReqChangeData: accessed-variable=rSR_PowerSystemStateReqChange.PowerSystemStateReqChangeData
              DRA_rSR_RTT_Icon_RTT_IconData: accessed-variable=rSR_RTT_Icon.RTT_IconData
              DRA_rSR_RTT_Status_RTT_StatusData: accessed-variable=rSR_RTT_Status.RTT_StatusData
              DRA_rSR_RTT_Toggle_RTT_ToggleData: accessed-variable=rSR_RTT_Toggle.RTT_ToggleData
              DRA_rSR_ShiftPosIndStatus_ShiftPosIndStatusData: accessed-variable=rSR_ShiftPosIndStatus.ShiftPosIndStatusData
              DRA_rSR_SlowGaugeInfo_SlowGaugeInfoData: accessed-variable=rSR_SlowGaugeInfo.SlowGaugeInfoData
              DRA_rSR_TpmsWarningData_TpmsWarningDataData: accessed-variable=rSR_TpmsWarningData.TpmsWarningDataData
              DRA_rSR_TT_Status_TT_StatusData: accessed-variable=rSR_TT_Status.TT_StatusData
              DRA_rSR_WarningDisplay_WarningDisplayData: accessed-variable=rSR_WarningDisplay.WarningDisplayData
              DRA_rSR_WarningExtDisplay_WarningExtDisplayData: accessed-variable=rSR_WarningExtDisplay.WarningExtDisplayData
              DRP_rSR_DiagDIDRequest_DiagDIDRequestData: accessed-variable=rSR_DiagDIDRequest.DiagDIDRequestData
              DRP_rSR_DiagIOCtrlRequest_DiagIOCtrlRequestData: accessed-variable=rSR_DiagIOCtrlRequest.DiagIOCtrlRequestData
              DRP_rSR_DiagRoutineRequest_DiagRoutineRequestData: accessed-variable=rSR_DiagRoutineRequest.DiagRoutineRequestData
              DRP_rSR_HealthDumpGetData_HealthDumpGetDataData: accessed-variable=rSR_HealthDumpGetData.HealthDumpGetDataData
              DRP_rSR_HealthDumpGetHdr_HealthDumpGetHdrData: accessed-variable=rSR_HealthDumpGetHdr.HealthDumpGetHdrData
              DRP_rSR_IgnState_IgnStateData: accessed-variable=rSR_IgnState.IgnStateData
              DRP_rSR_UpdateLongServiceReq_UpdateLongServiceReqData: accessed-variable=rSR_UpdateLongServiceReq.UpdateLongServiceReqData
              DRP_rSR_UpdateShortServiceReq_UpdateShortServiceReqData: accessed-variable=rSR_UpdateShortServiceReq.UpdateShortServiceReqData
          data-send-points:
            17 x access:
              DSP_pSR_DiagResponse_DiagResponseData: accessed-variable=pSR_DiagResponse.DiagResponseData
              DSP_pSR_HealthDomainFatalError_HealthDomainFatalErrorData: accessed-variable=pSR_HealthDomainFatalError.HealthDomainFatalErrorData
              DSP_pSR_HealthDomainHeartbeat_HealthDomainHeartbeatData: accessed-variable=pSR_HealthDomainHeartbeat.HealthDomainHeartbeatData
              DSP_pSR_HealthDumpData_HealthDumpDataData: accessed-variable=pSR_HealthDumpData.HealthDumpDataData
              DSP_pSR_HealthDumpHdrInfo_HealthDumpHdrInfoData: accessed-variable=pSR_HealthDumpHdrInfo.HealthDumpHdrInfoData
              DSP_pSR_HealthEventRecord_HealthEventRecordData: accessed-variable=pSR_HealthEventRecord.HealthEventRecordData
              DSP_pSR_MainHMIReadyStatus_MainHMIReadyStatusData: accessed-variable=pSR_MainHMIReadyStatus.MainHMIReadyStatusData
              DSP_pSR_PowerExtendShutdownTime_PowerExtendShutdownTimeData: accessed-variable=pSR_PowerExtendShutdownTime.PowerExtendShutdownTimeData
              DSP_pSR_PowerKeepSystemAwake_PowerKeepSystemAwakeData: accessed-variable=pSR_PowerKeepSystemAwake.PowerKeepSystemAwakeData
              DSP_pSR_SafeHMIReadyStatus_SafeHMIReadyStatusData: accessed-variable=pSR_SafeHMIReadyStatus.SafeHMIReadyStatusData
              DSP_pSR_UpdateShortServiceResp_UpdateShortServiceRespData: accessed-variable=pSR_UpdateShortServiceResp.UpdateShortServiceRespData
              DWA_pSR_DisplayCurrentState_DisplayCurrentStateData: accessed-variable=pSR_DisplayCurrentState.DisplayCurrentStateData
              DWA_pSR_EmmcErrorNotifier_EmmcErrorNotifierData: accessed-variable=pSR_EmmcErrorNotifier.EmmcErrorNotifierData
              DWA_pSR_HudWarningStatus_HudWarningStatusData: accessed-variable=pSR_HudWarningStatus.HudWarningStatusData
              DWA_pSR_PowerSystemState_PowerSystemStateData: accessed-variable=pSR_PowerSystemState.PowerSystemStateData
              DWA_pSR_WarningDisplayAvailable_WarningDisplayAvailableData: accessed-variable=pSR_WarningDisplayAvailable.WarningDisplayAvailableData
              DWA_pSR_WarningStatus_WarningStatusData: accessed-variable=pSR_WarningStatus.WarningStatusData
          sync call OA_rCS_UclSystemCallbacks_ErrorNotification: operation=rCS_UclSystemCallbacks.ErrorNotification, timeout=0
          sync call OA_rCS_UclSystemCallbacks_LinkStatusChanged: operation=rCS_UclSystemCallbacks.LinkStatusChanged, timeout=0
        OnDre_TT_Status
          data-receive-point-by-arguments:
            23 x access:
              DRA_rSR_DisplaySetPower_DisplaySetPowerData: accessed-variable=rSR_DisplaySetPower.DisplaySetPowerData
              DRA_rSR_FastGaugeInfo_FastGaugeInfoData: accessed-variable=rSR_FastGaugeInfo.FastGaugeInfoData
              DRA_rSR_FRTT_Status_FRTT_StatusData: accessed-variable=rSR_FRTT_Status.FRTT_StatusData
              DRA_rSR_HudWarningDisplay_HudWarningDisplayData: accessed-variable=rSR_HudWarningDisplay.HudWarningDisplayData
              DRA_rSR_IlluminationData_IlluminationDataData: accessed-variable=rSR_IlluminationData.IlluminationDataData
              DRA_rSR_PowerSystemStateReqChange_PowerSystemStateReqChangeData: accessed-variable=rSR_PowerSystemStateReqChange.PowerSystemStateReqChangeData
              DRA_rSR_RTT_Icon_RTT_IconData: accessed-variable=rSR_RTT_Icon.RTT_IconData
              DRA_rSR_RTT_Status_RTT_StatusData: accessed-variable=rSR_RTT_Status.RTT_StatusData
              DRA_rSR_RTT_Toggle_RTT_ToggleData: accessed-variable=rSR_RTT_Toggle.RTT_ToggleData
              DRA_rSR_ShiftPosIndStatus_ShiftPosIndStatusData: accessed-variable=rSR_ShiftPosIndStatus.ShiftPosIndStatusData
              DRA_rSR_SlowGaugeInfo_SlowGaugeInfoData: accessed-variable=rSR_SlowGaugeInfo.SlowGaugeInfoData
              DRA_rSR_TpmsWarningData_TpmsWarningDataData: accessed-variable=rSR_TpmsWarningData.TpmsWarningDataData
              DRA_rSR_TT_Status_TT_StatusData: accessed-variable=rSR_TT_Status.TT_StatusData
              DRA_rSR_WarningDisplay_WarningDisplayData: accessed-variable=rSR_WarningDisplay.WarningDisplayData
              DRA_rSR_WarningExtDisplay_WarningExtDisplayData: accessed-variable=rSR_WarningExtDisplay.WarningExtDisplayData
              DRP_rSR_DiagDIDRequest_DiagDIDRequestData: accessed-variable=rSR_DiagDIDRequest.DiagDIDRequestData
              DRP_rSR_DiagIOCtrlRequest_DiagIOCtrlRequestData: accessed-variable=rSR_DiagIOCtrlRequest.DiagIOCtrlRequestData
              DRP_rSR_DiagRoutineRequest_DiagRoutineRequestData: accessed-variable=rSR_DiagRoutineRequest.DiagRoutineRequestData
              DRP_rSR_HealthDumpGetData_HealthDumpGetDataData: accessed-variable=rSR_HealthDumpGetData.HealthDumpGetDataData
              DRP_rSR_HealthDumpGetHdr_HealthDumpGetHdrData: accessed-variable=rSR_HealthDumpGetHdr.HealthDumpGetHdrData
              DRP_rSR_IgnState_IgnStateData: accessed-variable=rSR_IgnState.IgnStateData
              DRP_rSR_UpdateLongServiceReq_UpdateLongServiceReqData: accessed-variable=rSR_UpdateLongServiceReq.UpdateLongServiceReqData
              DRP_rSR_UpdateShortServiceReq_UpdateShortServiceReqData: accessed-variable=rSR_UpdateShortServiceReq.UpdateShortServiceReqData
          data-send-points:
            17 x access:
              DSP_pSR_DiagResponse_DiagResponseData: accessed-variable=pSR_DiagResponse.DiagResponseData
              DSP_pSR_HealthDomainFatalError_HealthDomainFatalErrorData: accessed-variable=pSR_HealthDomainFatalError.HealthDomainFatalErrorData
              DSP_pSR_HealthDomainHeartbeat_HealthDomainHeartbeatData: accessed-variable=pSR_HealthDomainHeartbeat.HealthDomainHeartbeatData
              DSP_pSR_HealthDumpData_HealthDumpDataData: accessed-variable=pSR_HealthDumpData.HealthDumpDataData
              DSP_pSR_HealthDumpHdrInfo_HealthDumpHdrInfoData: accessed-variable=pSR_HealthDumpHdrInfo.HealthDumpHdrInfoData
              DSP_pSR_HealthEventRecord_HealthEventRecordData: accessed-variable=pSR_HealthEventRecord.HealthEventRecordData
              DSP_pSR_MainHMIReadyStatus_MainHMIReadyStatusData: accessed-variable=pSR_MainHMIReadyStatus.MainHMIReadyStatusData
              DSP_pSR_PowerExtendShutdownTime_PowerExtendShutdownTimeData: accessed-variable=pSR_PowerExtendShutdownTime.PowerExtendShutdownTimeData
              DSP_pSR_PowerKeepSystemAwake_PowerKeepSystemAwakeData: accessed-variable=pSR_PowerKeepSystemAwake.PowerKeepSystemAwakeData
              DSP_pSR_SafeHMIReadyStatus_SafeHMIReadyStatusData: accessed-variable=pSR_SafeHMIReadyStatus.SafeHMIReadyStatusData
              DSP_pSR_UpdateShortServiceResp_UpdateShortServiceRespData: accessed-variable=pSR_UpdateShortServiceResp.UpdateShortServiceRespData
              DWA_pSR_DisplayCurrentState_DisplayCurrentStateData: accessed-variable=pSR_DisplayCurrentState.DisplayCurrentStateData
              DWA_pSR_EmmcErrorNotifier_EmmcErrorNotifierData: accessed-variable=pSR_EmmcErrorNotifier.EmmcErrorNotifierData
              DWA_pSR_HudWarningStatus_HudWarningStatusData: accessed-variable=pSR_HudWarningStatus.HudWarningStatusData
              DWA_pSR_PowerSystemState_PowerSystemStateData: accessed-variable=pSR_PowerSystemState.PowerSystemStateData
              DWA_pSR_WarningDisplayAvailable_WarningDisplayAvailableData: accessed-variable=pSR_WarningDisplayAvailable.WarningDisplayAvailableData
              DWA_pSR_WarningStatus_WarningStatusData: accessed-variable=pSR_WarningStatus.WarningStatusData
          sync call OA_rCS_UclSystemCallbacks_ErrorNotification: operation=rCS_UclSystemCallbacks.ErrorNotification, timeout=0
          sync call OA_rCS_UclSystemCallbacks_LinkStatusChanged: operation=rCS_UclSystemCallbacks.LinkStatusChanged, timeout=0
        OnDre_UpdateLongServiceReq
          data-receive-point-by-arguments:
            23 x access:
              DRA_rSR_DisplaySetPower_DisplaySetPowerData: accessed-variable=rSR_DisplaySetPower.DisplaySetPowerData
              DRA_rSR_FastGaugeInfo_FastGaugeInfoData: accessed-variable=rSR_FastGaugeInfo.FastGaugeInfoData
              DRA_rSR_FRTT_Status_FRTT_StatusData: accessed-variable=rSR_FRTT_Status.FRTT_StatusData
              DRA_rSR_HudWarningDisplay_HudWarningDisplayData: accessed-variable=rSR_HudWarningDisplay.HudWarningDisplayData
              DRA_rSR_IlluminationData_IlluminationDataData: accessed-variable=rSR_IlluminationData.IlluminationDataData
              DRA_rSR_PowerSystemStateReqChange_PowerSystemStateReqChangeData: accessed-variable=rSR_PowerSystemStateReqChange.PowerSystemStateReqChangeData
              DRA_rSR_RTT_Icon_RTT_IconData: accessed-variable=rSR_RTT_Icon.RTT_IconData
              DRA_rSR_RTT_Status_RTT_StatusData: accessed-variable=rSR_RTT_Status.RTT_StatusData
              DRA_rSR_RTT_Toggle_RTT_ToggleData: accessed-variable=rSR_RTT_Toggle.RTT_ToggleData
              DRA_rSR_ShiftPosIndStatus_ShiftPosIndStatusData: accessed-variable=rSR_ShiftPosIndStatus.ShiftPosIndStatusData
              DRA_rSR_SlowGaugeInfo_SlowGaugeInfoData: accessed-variable=rSR_SlowGaugeInfo.SlowGaugeInfoData
              DRA_rSR_TpmsWarningData_TpmsWarningDataData: accessed-variable=rSR_TpmsWarningData.TpmsWarningDataData
              DRA_rSR_TT_Status_TT_StatusData: accessed-variable=rSR_TT_Status.TT_StatusData
              DRA_rSR_WarningDisplay_WarningDisplayData: accessed-variable=rSR_WarningDisplay.WarningDisplayData
              DRA_rSR_WarningExtDisplay_WarningExtDisplayData: accessed-variable=rSR_WarningExtDisplay.WarningExtDisplayData
              DRP_rSR_DiagDIDRequest_DiagDIDRequestData: accessed-variable=rSR_DiagDIDRequest.DiagDIDRequestData
              DRP_rSR_DiagIOCtrlRequest_DiagIOCtrlRequestData: accessed-variable=rSR_DiagIOCtrlRequest.DiagIOCtrlRequestData
              DRP_rSR_DiagRoutineRequest_DiagRoutineRequestData: accessed-variable=rSR_DiagRoutineRequest.DiagRoutineRequestData
              DRP_rSR_HealthDumpGetData_HealthDumpGetDataData: accessed-variable=rSR_HealthDumpGetData.HealthDumpGetDataData
              DRP_rSR_HealthDumpGetHdr_HealthDumpGetHdrData: accessed-variable=rSR_HealthDumpGetHdr.HealthDumpGetHdrData
              DRP_rSR_IgnState_IgnStateData: accessed-variable=rSR_IgnState.IgnStateData
              DRP_rSR_UpdateLongServiceReq_UpdateLongServiceReqData: accessed-variable=rSR_UpdateLongServiceReq.UpdateLongServiceReqData
              DRP_rSR_UpdateShortServiceReq_UpdateShortServiceReqData: accessed-variable=rSR_UpdateShortServiceReq.UpdateShortServiceReqData
          data-send-points:
            17 x access:
              DSP_pSR_DiagResponse_DiagResponseData: accessed-variable=pSR_DiagResponse.DiagResponseData
              DSP_pSR_HealthDomainFatalError_HealthDomainFatalErrorData: accessed-variable=pSR_HealthDomainFatalError.HealthDomainFatalErrorData
              DSP_pSR_HealthDomainHeartbeat_HealthDomainHeartbeatData: accessed-variable=pSR_HealthDomainHeartbeat.HealthDomainHeartbeatData
              DSP_pSR_HealthDumpData_HealthDumpDataData: accessed-variable=pSR_HealthDumpData.HealthDumpDataData
              DSP_pSR_HealthDumpHdrInfo_HealthDumpHdrInfoData: accessed-variable=pSR_HealthDumpHdrInfo.HealthDumpHdrInfoData
              DSP_pSR_HealthEventRecord_HealthEventRecordData: accessed-variable=pSR_HealthEventRecord.HealthEventRecordData
              DSP_pSR_MainHMIReadyStatus_MainHMIReadyStatusData: accessed-variable=pSR_MainHMIReadyStatus.MainHMIReadyStatusData
              DSP_pSR_PowerExtendShutdownTime_PowerExtendShutdownTimeData: accessed-variable=pSR_PowerExtendShutdownTime.PowerExtendShutdownTimeData
              DSP_pSR_PowerKeepSystemAwake_PowerKeepSystemAwakeData: accessed-variable=pSR_PowerKeepSystemAwake.PowerKeepSystemAwakeData
              DSP_pSR_SafeHMIReadyStatus_SafeHMIReadyStatusData: accessed-variable=pSR_SafeHMIReadyStatus.SafeHMIReadyStatusData
              DSP_pSR_UpdateShortServiceResp_UpdateShortServiceRespData: accessed-variable=pSR_UpdateShortServiceResp.UpdateShortServiceRespData
              DWA_pSR_DisplayCurrentState_DisplayCurrentStateData: accessed-variable=pSR_DisplayCurrentState.DisplayCurrentStateData
              DWA_pSR_EmmcErrorNotifier_EmmcErrorNotifierData: accessed-variable=pSR_EmmcErrorNotifier.EmmcErrorNotifierData
              DWA_pSR_HudWarningStatus_HudWarningStatusData: accessed-variable=pSR_HudWarningStatus.HudWarningStatusData
              DWA_pSR_PowerSystemState_PowerSystemStateData: accessed-variable=pSR_PowerSystemState.PowerSystemStateData
              DWA_pSR_WarningDisplayAvailable_WarningDisplayAvailableData: accessed-variable=pSR_WarningDisplayAvailable.WarningDisplayAvailableData
              DWA_pSR_WarningStatus_WarningStatusData: accessed-variable=pSR_WarningStatus.WarningStatusData
          sync call OA_rCS_UclSystemCallbacks_ErrorNotification: operation=rCS_UclSystemCallbacks.ErrorNotification, timeout=0
          sync call OA_rCS_UclSystemCallbacks_LinkStatusChanged: operation=rCS_UclSystemCallbacks.LinkStatusChanged, timeout=0
        OnDre_UpdateShortServiceReq
          data-receive-point-by-arguments:
            23 x access:
              DRA_rSR_DisplaySetPower_DisplaySetPowerData: accessed-variable=rSR_DisplaySetPower.DisplaySetPowerData
              DRA_rSR_FastGaugeInfo_FastGaugeInfoData: accessed-variable=rSR_FastGaugeInfo.FastGaugeInfoData
              DRA_rSR_FRTT_Status_FRTT_StatusData: accessed-variable=rSR_FRTT_Status.FRTT_StatusData
              DRA_rSR_HudWarningDisplay_HudWarningDisplayData: accessed-variable=rSR_HudWarningDisplay.HudWarningDisplayData
              DRA_rSR_IlluminationData_IlluminationDataData: accessed-variable=rSR_IlluminationData.IlluminationDataData
              DRA_rSR_PowerSystemStateReqChange_PowerSystemStateReqChangeData: accessed-variable=rSR_PowerSystemStateReqChange.PowerSystemStateReqChangeData
              DRA_rSR_RTT_Icon_RTT_IconData: accessed-variable=rSR_RTT_Icon.RTT_IconData
              DRA_rSR_RTT_Status_RTT_StatusData: accessed-variable=rSR_RTT_Status.RTT_StatusData
              DRA_rSR_RTT_Toggle_RTT_ToggleData: accessed-variable=rSR_RTT_Toggle.RTT_ToggleData
              DRA_rSR_ShiftPosIndStatus_ShiftPosIndStatusData: accessed-variable=rSR_ShiftPosIndStatus.ShiftPosIndStatusData
              DRA_rSR_SlowGaugeInfo_SlowGaugeInfoData: accessed-variable=rSR_SlowGaugeInfo.SlowGaugeInfoData
              DRA_rSR_TpmsWarningData_TpmsWarningDataData: accessed-variable=rSR_TpmsWarningData.TpmsWarningDataData
              DRA_rSR_TT_Status_TT_StatusData: accessed-variable=rSR_TT_Status.TT_StatusData
              DRA_rSR_WarningDisplay_WarningDisplayData: accessed-variable=rSR_WarningDisplay.WarningDisplayData
              DRA_rSR_WarningExtDisplay_WarningExtDisplayData: accessed-variable=rSR_WarningExtDisplay.WarningExtDisplayData
              DRP_rSR_DiagDIDRequest_DiagDIDRequestData: accessed-variable=rSR_DiagDIDRequest.DiagDIDRequestData
              DRP_rSR_DiagIOCtrlRequest_DiagIOCtrlRequestData: accessed-variable=rSR_DiagIOCtrlRequest.DiagIOCtrlRequestData
              DRP_rSR_DiagRoutineRequest_DiagRoutineRequestData: accessed-variable=rSR_DiagRoutineRequest.DiagRoutineRequestData
              DRP_rSR_HealthDumpGetData_HealthDumpGetDataData: accessed-variable=rSR_HealthDumpGetData.HealthDumpGetDataData
              DRP_rSR_HealthDumpGetHdr_HealthDumpGetHdrData: accessed-variable=rSR_HealthDumpGetHdr.HealthDumpGetHdrData
              DRP_rSR_IgnState_IgnStateData: accessed-variable=rSR_IgnState.IgnStateData
              DRP_rSR_UpdateLongServiceReq_UpdateLongServiceReqData: accessed-variable=rSR_UpdateLongServiceReq.UpdateLongServiceReqData
              DRP_rSR_UpdateShortServiceReq_UpdateShortServiceReqData: accessed-variable=rSR_UpdateShortServiceReq.UpdateShortServiceReqData
          data-send-points:
            17 x access:
              DSP_pSR_DiagResponse_DiagResponseData: accessed-variable=pSR_DiagResponse.DiagResponseData
              DSP_pSR_HealthDomainFatalError_HealthDomainFatalErrorData: accessed-variable=pSR_HealthDomainFatalError.HealthDomainFatalErrorData
              DSP_pSR_HealthDomainHeartbeat_HealthDomainHeartbeatData: accessed-variable=pSR_HealthDomainHeartbeat.HealthDomainHeartbeatData
              DSP_pSR_HealthDumpData_HealthDumpDataData: accessed-variable=pSR_HealthDumpData.HealthDumpDataData
              DSP_pSR_HealthDumpHdrInfo_HealthDumpHdrInfoData: accessed-variable=pSR_HealthDumpHdrInfo.HealthDumpHdrInfoData
              DSP_pSR_HealthEventRecord_HealthEventRecordData: accessed-variable=pSR_HealthEventRecord.HealthEventRecordData
              DSP_pSR_MainHMIReadyStatus_MainHMIReadyStatusData: accessed-variable=pSR_MainHMIReadyStatus.MainHMIReadyStatusData
              DSP_pSR_PowerExtendShutdownTime_PowerExtendShutdownTimeData: accessed-variable=pSR_PowerExtendShutdownTime.PowerExtendShutdownTimeData
              DSP_pSR_PowerKeepSystemAwake_PowerKeepSystemAwakeData: accessed-variable=pSR_PowerKeepSystemAwake.PowerKeepSystemAwakeData
              DSP_pSR_SafeHMIReadyStatus_SafeHMIReadyStatusData: accessed-variable=pSR_SafeHMIReadyStatus.SafeHMIReadyStatusData
              DSP_pSR_UpdateShortServiceResp_UpdateShortServiceRespData: accessed-variable=pSR_UpdateShortServiceResp.UpdateShortServiceRespData
              DWA_pSR_DisplayCurrentState_DisplayCurrentStateData: accessed-variable=pSR_DisplayCurrentState.DisplayCurrentStateData
              DWA_pSR_EmmcErrorNotifier_EmmcErrorNotifierData: accessed-variable=pSR_EmmcErrorNotifier.EmmcErrorNotifierData
              DWA_pSR_HudWarningStatus_HudWarningStatusData: accessed-variable=pSR_HudWarningStatus.HudWarningStatusData
              DWA_pSR_PowerSystemState_PowerSystemStateData: accessed-variable=pSR_PowerSystemState.PowerSystemStateData
              DWA_pSR_WarningDisplayAvailable_WarningDisplayAvailableData: accessed-variable=pSR_WarningDisplayAvailable.WarningDisplayAvailableData
              DWA_pSR_WarningStatus_WarningStatusData: accessed-variable=pSR_WarningStatus.WarningStatusData
          sync call OA_rCS_UclSystemCallbacks_ErrorNotification: operation=rCS_UclSystemCallbacks.ErrorNotification, timeout=0
          sync call OA_rCS_UclSystemCallbacks_LinkStatusChanged: operation=rCS_UclSystemCallbacks.LinkStatusChanged, timeout=0
        OnDre_WarningDisplay
          data-receive-point-by-arguments:
            23 x access:
              DRA_rSR_DisplaySetPower_DisplaySetPowerData: accessed-variable=rSR_DisplaySetPower.DisplaySetPowerData
              DRA_rSR_FastGaugeInfo_FastGaugeInfoData: accessed-variable=rSR_FastGaugeInfo.FastGaugeInfoData
              DRA_rSR_FRTT_Status_FRTT_StatusData: accessed-variable=rSR_FRTT_Status.FRTT_StatusData
              DRA_rSR_HudWarningDisplay_HudWarningDisplayData: accessed-variable=rSR_HudWarningDisplay.HudWarningDisplayData
              DRA_rSR_IlluminationData_IlluminationDataData: accessed-variable=rSR_IlluminationData.IlluminationDataData
              DRA_rSR_PowerSystemStateReqChange_PowerSystemStateReqChangeData: accessed-variable=rSR_PowerSystemStateReqChange.PowerSystemStateReqChangeData
              DRA_rSR_RTT_Icon_RTT_IconData: accessed-variable=rSR_RTT_Icon.RTT_IconData
              DRA_rSR_RTT_Status_RTT_StatusData: accessed-variable=rSR_RTT_Status.RTT_StatusData
              DRA_rSR_RTT_Toggle_RTT_ToggleData: accessed-variable=rSR_RTT_Toggle.RTT_ToggleData
              DRA_rSR_ShiftPosIndStatus_ShiftPosIndStatusData: accessed-variable=rSR_ShiftPosIndStatus.ShiftPosIndStatusData
              DRA_rSR_SlowGaugeInfo_SlowGaugeInfoData: accessed-variable=rSR_SlowGaugeInfo.SlowGaugeInfoData
              DRA_rSR_TpmsWarningData_TpmsWarningDataData: accessed-variable=rSR_TpmsWarningData.TpmsWarningDataData
              DRA_rSR_TT_Status_TT_StatusData: accessed-variable=rSR_TT_Status.TT_StatusData
              DRA_rSR_WarningDisplay_WarningDisplayData: accessed-variable=rSR_WarningDisplay.WarningDisplayData
              DRA_rSR_WarningExtDisplay_WarningExtDisplayData: accessed-variable=rSR_WarningExtDisplay.WarningExtDisplayData
              DRP_rSR_DiagDIDRequest_DiagDIDRequestData: accessed-variable=rSR_DiagDIDRequest.DiagDIDRequestData
              DRP_rSR_DiagIOCtrlRequest_DiagIOCtrlRequestData: accessed-variable=rSR_DiagIOCtrlRequest.DiagIOCtrlRequestData
              DRP_rSR_DiagRoutineRequest_DiagRoutineRequestData: accessed-variable=rSR_DiagRoutineRequest.DiagRoutineRequestData
              DRP_rSR_HealthDumpGetData_HealthDumpGetDataData: accessed-variable=rSR_HealthDumpGetData.HealthDumpGetDataData
              DRP_rSR_HealthDumpGetHdr_HealthDumpGetHdrData: accessed-variable=rSR_HealthDumpGetHdr.HealthDumpGetHdrData
              DRP_rSR_IgnState_IgnStateData: accessed-variable=rSR_IgnState.IgnStateData
              DRP_rSR_UpdateLongServiceReq_UpdateLongServiceReqData: accessed-variable=rSR_UpdateLongServiceReq.UpdateLongServiceReqData
              DRP_rSR_UpdateShortServiceReq_UpdateShortServiceReqData: accessed-variable=rSR_UpdateShortServiceReq.UpdateShortServiceReqData
          data-send-points:
            17 x access:
              DSP_pSR_DiagResponse_DiagResponseData: accessed-variable=pSR_DiagResponse.DiagResponseData
              DSP_pSR_HealthDomainFatalError_HealthDomainFatalErrorData: accessed-variable=pSR_HealthDomainFatalError.HealthDomainFatalErrorData
              DSP_pSR_HealthDomainHeartbeat_HealthDomainHeartbeatData: accessed-variable=pSR_HealthDomainHeartbeat.HealthDomainHeartbeatData
              DSP_pSR_HealthDumpData_HealthDumpDataData: accessed-variable=pSR_HealthDumpData.HealthDumpDataData
              DSP_pSR_HealthDumpHdrInfo_HealthDumpHdrInfoData: accessed-variable=pSR_HealthDumpHdrInfo.HealthDumpHdrInfoData
              DSP_pSR_HealthEventRecord_HealthEventRecordData: accessed-variable=pSR_HealthEventRecord.HealthEventRecordData
              DSP_pSR_MainHMIReadyStatus_MainHMIReadyStatusData: accessed-variable=pSR_MainHMIReadyStatus.MainHMIReadyStatusData
              DSP_pSR_PowerExtendShutdownTime_PowerExtendShutdownTimeData: accessed-variable=pSR_PowerExtendShutdownTime.PowerExtendShutdownTimeData
              DSP_pSR_PowerKeepSystemAwake_PowerKeepSystemAwakeData: accessed-variable=pSR_PowerKeepSystemAwake.PowerKeepSystemAwakeData
              DSP_pSR_SafeHMIReadyStatus_SafeHMIReadyStatusData: accessed-variable=pSR_SafeHMIReadyStatus.SafeHMIReadyStatusData
              DSP_pSR_UpdateShortServiceResp_UpdateShortServiceRespData: accessed-variable=pSR_UpdateShortServiceResp.UpdateShortServiceRespData
              DWA_pSR_DisplayCurrentState_DisplayCurrentStateData: accessed-variable=pSR_DisplayCurrentState.DisplayCurrentStateData
              DWA_pSR_EmmcErrorNotifier_EmmcErrorNotifierData: accessed-variable=pSR_EmmcErrorNotifier.EmmcErrorNotifierData
              DWA_pSR_HudWarningStatus_HudWarningStatusData: accessed-variable=pSR_HudWarningStatus.HudWarningStatusData
              DWA_pSR_PowerSystemState_PowerSystemStateData: accessed-variable=pSR_PowerSystemState.PowerSystemStateData
              DWA_pSR_WarningDisplayAvailable_WarningDisplayAvailableData: accessed-variable=pSR_WarningDisplayAvailable.WarningDisplayAvailableData
              DWA_pSR_WarningStatus_WarningStatusData: accessed-variable=pSR_WarningStatus.WarningStatusData
          sync call OA_rCS_UclSystemCallbacks_ErrorNotification: operation=rCS_UclSystemCallbacks.ErrorNotification, timeout=0
          sync call OA_rCS_UclSystemCallbacks_LinkStatusChanged: operation=rCS_UclSystemCallbacks.LinkStatusChanged, timeout=0
        OnDre_WarningExtDisplay
          data-receive-point-by-arguments:
            23 x access:
              DRA_rSR_DisplaySetPower_DisplaySetPowerData: accessed-variable=rSR_DisplaySetPower.DisplaySetPowerData
              DRA_rSR_FastGaugeInfo_FastGaugeInfoData: accessed-variable=rSR_FastGaugeInfo.FastGaugeInfoData
              DRA_rSR_FRTT_Status_FRTT_StatusData: accessed-variable=rSR_FRTT_Status.FRTT_StatusData
              DRA_rSR_HudWarningDisplay_HudWarningDisplayData: accessed-variable=rSR_HudWarningDisplay.HudWarningDisplayData
              DRA_rSR_IlluminationData_IlluminationDataData: accessed-variable=rSR_IlluminationData.IlluminationDataData
              DRA_rSR_PowerSystemStateReqChange_PowerSystemStateReqChangeData: accessed-variable=rSR_PowerSystemStateReqChange.PowerSystemStateReqChangeData
              DRA_rSR_RTT_Icon_RTT_IconData: accessed-variable=rSR_RTT_Icon.RTT_IconData
              DRA_rSR_RTT_Status_RTT_StatusData: accessed-variable=rSR_RTT_Status.RTT_StatusData
              DRA_rSR_RTT_Toggle_RTT_ToggleData: accessed-variable=rSR_RTT_Toggle.RTT_ToggleData
              DRA_rSR_ShiftPosIndStatus_ShiftPosIndStatusData: accessed-variable=rSR_ShiftPosIndStatus.ShiftPosIndStatusData
              DRA_rSR_SlowGaugeInfo_SlowGaugeInfoData: accessed-variable=rSR_SlowGaugeInfo.SlowGaugeInfoData
              DRA_rSR_TpmsWarningData_TpmsWarningDataData: accessed-variable=rSR_TpmsWarningData.TpmsWarningDataData
              DRA_rSR_TT_Status_TT_StatusData: accessed-variable=rSR_TT_Status.TT_StatusData
              DRA_rSR_WarningDisplay_WarningDisplayData: accessed-variable=rSR_WarningDisplay.WarningDisplayData
              DRA_rSR_WarningExtDisplay_WarningExtDisplayData: accessed-variable=rSR_WarningExtDisplay.WarningExtDisplayData
              DRP_rSR_DiagDIDRequest_DiagDIDRequestData: accessed-variable=rSR_DiagDIDRequest.DiagDIDRequestData
              DRP_rSR_DiagIOCtrlRequest_DiagIOCtrlRequestData: accessed-variable=rSR_DiagIOCtrlRequest.DiagIOCtrlRequestData
              DRP_rSR_DiagRoutineRequest_DiagRoutineRequestData: accessed-variable=rSR_DiagRoutineRequest.DiagRoutineRequestData
              DRP_rSR_HealthDumpGetData_HealthDumpGetDataData: accessed-variable=rSR_HealthDumpGetData.HealthDumpGetDataData
              DRP_rSR_HealthDumpGetHdr_HealthDumpGetHdrData: accessed-variable=rSR_HealthDumpGetHdr.HealthDumpGetHdrData
              DRP_rSR_IgnState_IgnStateData: accessed-variable=rSR_IgnState.IgnStateData
              DRP_rSR_UpdateLongServiceReq_UpdateLongServiceReqData: accessed-variable=rSR_UpdateLongServiceReq.UpdateLongServiceReqData
              DRP_rSR_UpdateShortServiceReq_UpdateShortServiceReqData: accessed-variable=rSR_UpdateShortServiceReq.UpdateShortServiceReqData
          data-send-points:
            17 x access:
              DSP_pSR_DiagResponse_DiagResponseData: accessed-variable=pSR_DiagResponse.DiagResponseData
              DSP_pSR_HealthDomainFatalError_HealthDomainFatalErrorData: accessed-variable=pSR_HealthDomainFatalError.HealthDomainFatalErrorData
              DSP_pSR_HealthDomainHeartbeat_HealthDomainHeartbeatData: accessed-variable=pSR_HealthDomainHeartbeat.HealthDomainHeartbeatData
              DSP_pSR_HealthDumpData_HealthDumpDataData: accessed-variable=pSR_HealthDumpData.HealthDumpDataData
              DSP_pSR_HealthDumpHdrInfo_HealthDumpHdrInfoData: accessed-variable=pSR_HealthDumpHdrInfo.HealthDumpHdrInfoData
              DSP_pSR_HealthEventRecord_HealthEventRecordData: accessed-variable=pSR_HealthEventRecord.HealthEventRecordData
              DSP_pSR_MainHMIReadyStatus_MainHMIReadyStatusData: accessed-variable=pSR_MainHMIReadyStatus.MainHMIReadyStatusData
              DSP_pSR_PowerExtendShutdownTime_PowerExtendShutdownTimeData: accessed-variable=pSR_PowerExtendShutdownTime.PowerExtendShutdownTimeData
              DSP_pSR_PowerKeepSystemAwake_PowerKeepSystemAwakeData: accessed-variable=pSR_PowerKeepSystemAwake.PowerKeepSystemAwakeData
              DSP_pSR_SafeHMIReadyStatus_SafeHMIReadyStatusData: accessed-variable=pSR_SafeHMIReadyStatus.SafeHMIReadyStatusData
              DSP_pSR_UpdateShortServiceResp_UpdateShortServiceRespData: accessed-variable=pSR_UpdateShortServiceResp.UpdateShortServiceRespData
              DWA_pSR_DisplayCurrentState_DisplayCurrentStateData: accessed-variable=pSR_DisplayCurrentState.DisplayCurrentStateData
              DWA_pSR_EmmcErrorNotifier_EmmcErrorNotifierData: accessed-variable=pSR_EmmcErrorNotifier.EmmcErrorNotifierData
              DWA_pSR_HudWarningStatus_HudWarningStatusData: accessed-variable=pSR_HudWarningStatus.HudWarningStatusData
              DWA_pSR_PowerSystemState_PowerSystemStateData: accessed-variable=pSR_PowerSystemState.PowerSystemStateData
              DWA_pSR_WarningDisplayAvailable_WarningDisplayAvailableData: accessed-variable=pSR_WarningDisplayAvailable.WarningDisplayAvailableData
              DWA_pSR_WarningStatus_WarningStatusData: accessed-variable=pSR_WarningStatus.WarningStatusData
          sync call OA_rCS_UclSystemCallbacks_ErrorNotification: operation=rCS_UclSystemCallbacks.ErrorNotification, timeout=0
          sync call OA_rCS_UclSystemCallbacks_LinkStatusChanged: operation=rCS_UclSystemCallbacks.LinkStatusChanged, timeout=0
  21 x constant specification:
    UclProxyCddDisplayCurrentStateDataValue0: value-spec={short-label=UclProxyCddDisplayCurrentStateDataValue0, fields=[UclProxyCddDisplayCurrentStateDataValue_0:0, UclProxyCddDisplayCurrentStateDataValue_1:0]}
    UclProxyCddDisplaySetPowerDataValue0: value-spec={short-label=UclProxyCddDisplaySetPowerDataValue0, fields=[UclProxyCddDisplaySetPowerDataValue_0:0, UclProxyCddDisplaySetPowerDataValue_1:0]}
    UclProxyCddEmmcErrorNotifierDataValue0: value-spec={short-label=UclProxyCddEmmcErrorNotifierDataValue0, fields=UclProxyCddEmmcErrorNotifierDataValue_0:0}
    UclProxyCddFastGaugeInfoDataValue0: value-spec={short-label=UclProxyCddFastGaugeInfoDataValue0, fields=gaugeInfo:[fields=[id:0, position:0, digitalData:0, unit:0, dynData:0], fields=[id:0, position:0, digitalData:0, unit:0, dynData:0], fields=[id:0, position:0, digitalData:0, unit:0, dynData:0]]}
    UclProxyCddFRTT_StatusDataValue0: value-spec={short-label=UclProxyCddFRTT_StatusDataValue0, fields=UclProxyCddFRTT_StatusDataValue_0:[UclProxyCddmask0Value:0, UclProxyCddmask1Value:0]}
    UclProxyCddHudWarningDisplayDataValue0: value-spec={short-label=UclProxyCddHudWarningDisplayDataValue0, fields=[UclProxyCddHudWarningDisplayDataValue_0:0, UclProxyCddHudWarningDisplayDataValue_1:0, UclProxyCddHudWarningDisplayDataValue_2:[UclProxyCdddynData0Value:0, UclProxyCdddynData1Value:0, UclProxyCdddynData2Value:0, UclProxyCdddynData3Value:0, UclProxyCdddynData4Value:0, UclProxyCdddynData5Value:0, UclProxyCdddynData6Value:0, UclProxyCdddynData7Value:0]]}
    UclProxyCddHudWarningStatusDataValue0: value-spec={short-label=UclProxyCddHudWarningStatusDataValue0, fields=[UclProxyCddHudWarningStatusDataValue_0:0, UclProxyCddHudWarningStatusDataValue_1:0, UclProxyCddHudWarningStatusDataValue_2:[UclProxyCdddynData0Value:0, UclProxyCdddynData1Value:0, UclProxyCdddynData2Value:0, UclProxyCdddynData3Value:0, UclProxyCdddynData4Value:0, UclProxyCdddynData5Value:0, UclProxyCdddynData6Value:0, UclProxyCdddynData7Value:0, UclProxyCdddynData8Value:0, UclProxyCdddynData9Value:0]]}
    UclProxyCddIlluminationDataDataValue0: value-spec={short-label=UclProxyCddIlluminationDataDataValue0, fields=[UclProxyCddIlluminationDataDataValue_0:0, UclProxyCddIlluminationDataDataValue_1:0, UclProxyCddIlluminationDataDataValue_2:0, UclProxyCddIlluminationDataDataValue_3:0]}
    UclProxyCddPowerSystemStateDataValue0: value-spec={short-label=UclProxyCddPowerSystemStateDataValue0, fields=[UclProxyCddPowerSystemStateDataValue_0:0, UclProxyCddPowerSystemStateDataValue_1:0]}
    UclProxyCddPowerSystemStateReqChangeDataValue0: value-spec={short-label=UclProxyCddPowerSystemStateReqChangeDataValue0, fields=[UclProxyCddPowerSystemStateReqChangeDataValue_0:0, UclProxyCddPowerSystemStateReqChangeDataValue_1:0]}
    UclProxyCddRTT_IconDataValue0: value-spec={short-label=UclProxyCddRTT_IconDataValue0, fields=UclProxyCddRTT_IconDataValue_0:[UclProxyCddicon0Value:0, UclProxyCddicon1Value:0]}
    UclProxyCddRTT_StatusDataValue0: value-spec={short-label=UclProxyCddRTT_StatusDataValue0, fields=UclProxyCddRTT_StatusDataValue_0:[UclProxyCddmask0Value:0, UclProxyCddmask1Value:0]}
    UclProxyCddRTT_ToggleDataValue0: value-spec={short-label=UclProxyCddRTT_ToggleDataValue0, fields=[UclProxyCddRTT_ToggleDataValue_0:0, UclProxyCddRTT_ToggleDataValue_1:0]}
    UclProxyCddShiftPosIndStatusDataValue0: value-spec={short-label=UclProxyCddShiftPosIndStatusDataValue0, fields={short-label=UclProxyCddShiftPosIndStatusDataValue_0, fields=[UclProxyCddstatusValue_0:0, UclProxyCddstatusValue_1:0, UclProxyCddstatusValue_2:0, UclProxyCddstatusValue_3:0, UclProxyCddstatusValue_4:0, UclProxyCddstatusValue_5:0]}}
    UclProxyCddSlowGaugeInfoDataValue0: value-spec={short-label=UclProxyCddSlowGaugeInfoDataValue0, fields={short-label=UclProxyCddSlowGaugeInfoDataValue_0, fields=[UclProxyCddgaugeInfoValue_0:0, UclProxyCddgaugeInfoValue_1:0, UclProxyCddgaugeInfoValue_2:0, UclProxyCddgaugeInfoValue_3:0, UclProxyCddgaugeInfoValue_4:0]}}
    UclProxyCddTpmsWarningDataDataValue0: value-spec={short-label=UclProxyCddTpmsWarningDataDataValue0, fields=UclProxyCddTpmsWarningDataDataValue_0:[UclProxyCddtpmsWarndata0Value:0, UclProxyCddtpmsWarndata1Value:0, UclProxyCddtpmsWarndata2Value:0, UclProxyCddtpmsWarndata3Value:0, UclProxyCddtpmsWarndata4Value:0]}
    UclProxyCddTT_StatusDataValue0: value-spec={short-label=UclProxyCddTT_StatusDataValue0, fields=UclProxyCddTT_StatusDataValue_0:[UclProxyCddmask0Value:0, UclProxyCddmask1Value:0, UclProxyCddmask2Value:0, UclProxyCddmask3Value:0, UclProxyCddmask4Value:0, UclProxyCddmask5Value:0, UclProxyCddmask6Value:0, UclProxyCddmask7Value:0, UclProxyCddmask8Value:0, UclProxyCddmask9Value:0, UclProxyCddmask10Value:0, UclProxyCddmask11Value:0, UclProxyCddmask12Value:0, UclProxyCddmask13Value:0, UclProxyCddmask14Value:0]}
    UclProxyCddWarningDisplayAvailableDataValue0: value-spec={short-label=UclProxyCddWarningDisplayAvailableDataValue0, fields=UclProxyCddWarningDisplayAvailableDataValue_0:0}
    UclProxyCddWarningDisplayDataValue0: value-spec={short-label=UclProxyCddWarningDisplayDataValue0, fields=[UclProxyCddWarningDisplayDataValue_0:0, UclProxyCddWarningDisplayDataValue_1:0, UclProxyCddWarningDisplayDataValue_2:[UclProxyCdddynData0Value:0, UclProxyCdddynData1Value:0, UclProxyCdddynData2Value:0, UclProxyCdddynData3Value:0, UclProxyCdddynData4Value:0, UclProxyCdddynData5Value:0, UclProxyCdddynData6Value:0, UclProxyCdddynData7Value:0]]}
    UclProxyCddWarningExtDisplayDataValue0: value-spec={short-label=UclProxyCddWarningExtDisplayDataValue0, fields=[UclProxyCddWarningExtDisplayDataValue_0:0, UclProxyCddWarningExtDisplayDataValue_1:0, UclProxyCddWarningExtDisplayDataValue_2:[UclProxyCdddynData0Value:0, UclProxyCdddynData1Value:0, UclProxyCdddynData2Value:0, UclProxyCdddynData3Value:0, UclProxyCdddynData4Value:0, UclProxyCdddynData5Value:0, UclProxyCdddynData6Value:0, UclProxyCdddynData7Value:0]]}
    UclProxyCddWarningStatusDataValue0: value-spec={short-label=UclProxyCddWarningStatusDataValue0, fields=[UclProxyCddWarningStatusDataValue_0:0, UclProxyCddWarningStatusDataValue_1:0, UclProxyCddWarningStatusDataValue_2:[UclProxyCdddynData0Value:0, UclProxyCdddynData1Value:0, UclProxyCdddynData2Value:0, UclProxyCdddynData3Value:0, UclProxyCdddynData4Value:0, UclProxyCdddynData5Value:0, UclProxyCdddynData6Value:0, UclProxyCdddynData7Value:0, UclProxyCdddynData8Value:0, UclProxyCdddynData9Value:0]]}
  swc implementation IMPL_UclProxyCdd: behavior=IB_UclProxyCdd
    code-descriptors:
      code Default: artifact-descriptors=autosar-engineering-object={short-label=Default, category=SWSRC}
package /E40_Platform_System_SystemPackage/Types
  client server interface if_CS_ModeOnCommand
    operation Impl_OnCommand: possible-error=if_CS_ModeOnCommand/E_NOT_OK
      arg cmdP: type=ECmpCmd, direction=IN, server-argument-impl-policy=USE-ARGUMENT-TYPE
    error E_NOT_OK: error-code=1
  client server interface UclInitShutdown
    operation Impl_Initialize: possible-error=UclInitShutdown/E_NOT_OK
    operation Impl_Shutdown: possible-error=UclInitShutdown/E_NOT_OK
    error E_NOT_OK: error-code=1
  client server interface UclSystemCallbacks
    operation ErrorNotification
      arg DLInst: type=UInt8, direction=IN, server-argument-impl-policy=USE-ARGUMENT-TYPE
      arg ErrorCode: type=SInt32, direction=IN, server-argument-impl-policy=USE-ARGUMENT-TYPE
    operation LinkStatusChanged
      arg DLInst: type=UInt8, direction=IN, server-argument-impl-policy=USE-ARGUMENT-TYPE
      arg Status: type=SInt32, direction=IN, server-argument-impl-policy=USE-ARGUMENT-TYPE
  62 x impl type:
    data_u32_5: category=ARRAY
      element ArrayElement: category=VALUE, array-size=5, array-size-semantics=FIXED-SIZE, base-type=uint32
    data_u8_10: category=ARRAY
      element ArrayElement: category=VALUE, array-size=10, array-size-semantics=FIXED-SIZE, base-type=uint8
    data_u8_15: category=ARRAY
      element ArrayElement: category=VALUE, array-size=15, array-size-semantics=FIXED-SIZE, base-type=uint8
    data_u8_2: category=ARRAY
      element ArrayElement: category=VALUE, array-size=2, array-size-semantics=FIXED-SIZE, base-type=uint8
    data_u8_256: category=ARRAY
      element ArrayElement: category=VALUE, array-size=256, array-size-semantics=FIXED-SIZE, base-type=uint8
    data_u8_32: category=ARRAY
      element ArrayElement: category=VALUE, array-size=32, array-size-semantics=FIXED-SIZE, base-type=uint8
    data_u8_512: category=ARRAY
      element ArrayElement: category=VALUE, array-size=512, array-size-semantics=FIXED-SIZE, base-type=uint8
    data_u8_64: category=ARRAY
      element ArrayElement: category=VALUE, array-size=64, array-size-semantics=FIXED-SIZE, base-type=uint8
    data_u8_8: category=ARRAY
      element ArrayElement: category=VALUE, array-size=8, array-size-semantics=FIXED-SIZE, base-type=uint8
    ECmpCmd: category=VALUE, base-type=uint8, compu {0=eCmpCmd_Init, 1=eCmpCmd_DeInit, 2=eCmpCmd_Activate, 3=eCmpCmd_DeActivate}, range raw 0..3
    EDidType: category=VALUE, base-type=uint8, compu {0=EDidType_Read, 1=EDidType_Write, 2=EDidType_Last}, range raw 0..2
    EDisplayPower: category=VALUE, base-type=uint8, compu {0=EDisplayPower_Off, 1=EDisplayPower_On, 2=EDisplayPower_Last}, range raw 0..2
    EDisplayStatus: category=VALUE, base-type=uint8, compu {0=EDisplayState_Off, 1=EDisplayState_On, 2=EDisplayState_Error, 3=EDisplayState_Disconnected, 4=EDisplayState_Last}, range raw 0..4
    EDomainId: category=VALUE, base-type=uint8, compu {0=EDomainId_VP, 1=EDomainId_Cluster, 2=EDomainId_IVI, 3=EDomainId_Last}, range raw 0..3
    EGaugeUnit: category=VALUE, base-type=uint8, compu {0=EGaugeUnit_Mph, 1=EGaugeUnit_Kmph, 2=EGaugeUnit_Centigrade, 3=EGaugeUnit_Farenheit, 4=EGaugeUnit_Psi, 5=EGaugeUnit_Pa, 6=EGaugeUnit_Bar, 7=EGaugeUnit_Kmpl, 8=EGaugeUnit_Mpg, 9=EGaugeUnit_Ltr, 10=EGaugeUnit_Gal, 11=EGaugeUnit_Km, 12=EGaugeUnit_Mile, 13=EGaugeUnit_Last}, range raw 0..13
    EIgnitionStatus: category=VALUE, base-type=uint8, compu {0=EIgnitionStatus_Off, 1=EIgnitionStatus_Acc, 2=EIgnitionStatus_Start, 3=EIgnitionStatus_Run, 4=EIgnitionStatus_Last}, range raw 0..4
    EIOCtrlOptType: category=VALUE, base-type=uint8, compu {0=EIOCtrlOptType_returnControlToECU, 1=EIOCtrlOptType_resetToDefault, 2=EIOCtrlOptType_freezeCurrentState, 3=EIOCtrlOptType_shortTermAdjustment, 4=EIOCtrlOptType_Last}, range raw 0..4
    ERoutineType: category=VALUE, base-type=uint8, compu {0=ERoutineType_Start, 1=ERoutineType_Stop, 2=ERoutineType_QueryResults, 3=ERoutineType_Last}, range raw 0..3
    ESystemState: category=VALUE, base-type=uint8, compu {0=ESystemState_Off, 1=ESystemState_Startup, 2=ESystemState_Up, 3=ESystemState_FullRun, 4=ESystemState_PrepareShutdown, 5=ESystemState_Minimal, 6=ESystemState_Shutdown, 7=ESystemState_Last}, range raw 0..7
    SDiagDIDRequest: category=STRUCTURE
      4 x element, all with category=TYPE_REFERENCE:
        did: implementation-data-type=UInt16
        didType: implementation-data-type=EDidType
        dataLen: implementation-data-type=UInt16
        data: implementation-data-type=data_u8_256
    SDiagIOCtrlRequest: category=STRUCTURE
      4 x element, all with category=TYPE_REFERENCE:
        did: implementation-data-type=UInt16
        optionCtrl: implementation-data-type=EIOCtrlOptType
        dataLen: implementation-data-type=UInt16
        data: implementation-data-type=data_u8_256
    SDiagResponse: category=STRUCTURE
      element responseCode: implementation-data-type=UInt8
      element dataLen: implementation-data-type=UInt16
      element data: implementation-data-type=data_u8_256
    SDiagRoutineRequest: category=STRUCTURE
      4 x element, all with category=TYPE_REFERENCE:
        routineId: implementation-data-type=UInt16
        routineType: implementation-data-type=ERoutineType
        dataLen: implementation-data-type=UInt16
        data: implementation-data-type=data_u8_256
    SDisplayCurrentState: category=STRUCTURE
      element displayId: implementation-data-type=UInt32
      element state: implementation-data-type=EDisplayStatus
    SDisplaySetPower: category=STRUCTURE
      element displayId: implementation-data-type=UInt32
      element state: implementation-data-type=EDisplayPower
    SEmmcErrorNotifier: category=STRUCTURE
      element errorCode: implementation-data-type=UInt32
    SFastGaugeInfo: category=STRUCTURE
      element gaugeInfo: implementation-data-type=SGaugeInfo_u32dyn_3
    SFRTT_Status: category=STRUCTURE
      element mask: implementation-data-type=data_u8_2
    SGaugeInfo: category=STRUCTURE
      5 x element, all with category=TYPE_REFERENCE:
        id: implementation-data-type=UInt8
        position: implementation-data-type=UInt16
        digitalData: implementation-data-type=SInt32
        unit: implementation-data-type=EGaugeUnit
        dynData: implementation-data-type=UInt16
    SGaugeInfo_u32dyn: category=STRUCTURE
      5 x element, all with category=TYPE_REFERENCE:
        id: implementation-data-type=UInt8
        position: implementation-data-type=UInt16
        digitalData: implementation-data-type=UInt32
        unit: implementation-data-type=EGaugeUnit
        dynData: implementation-data-type=UInt16
    SHealthDomainFatalError: category=STRUCTURE
      element domainId: implementation-data-type=EDomainId
      element compIdx: implementation-data-type=UInt32
    SHealthDomainHeartbeat: category=STRUCTURE
      element domainId: implementation-data-type=EDomainId
      element seqCnt: implementation-data-type=UInt32
    SHealthDumpData: category=STRUCTURE
      element chunkSize: implementation-data-type=UInt32
      element data: implementation-data-type=data_u8_32
    SHealthDumpGetData: category=STRUCTURE
      element reserved: implementation-data-type=UInt8
    SHealthDumpGetHdr: category=STRUCTURE
      element encrypt: implementation-data-type=UInt8
    SHealthDumpHdrInfo: category=STRUCTURE
      element fileSize: implementation-data-type=UInt32
    SHealthEventRecord: category=STRUCTURE
      element recordType: implementation-data-type=UInt8
      element recordLen: implementation-data-type=UInt8
      element recordData: implementation-data-type=data_u8_8
    SHudWarningDisplay: category=STRUCTURE
      element show: implementation-data-type=UInt8
      element warningId: implementation-data-type=UInt16
      element dynData: implementation-data-type=data_u8_8
    SHudWarningStatus: category=STRUCTURE
      element visible: implementation-data-type=UInt8
      element warningId: implementation-data-type=UInt16
      element dynData: implementation-data-type=data_u8_10
    SIgnState: category=STRUCTURE
      element state: implementation-data-type=EIgnitionStatus
    SIlluminationData: category=STRUCTURE
      4 x element, all with category=TYPE_REFERENCE, implementation-data-type=UInt8:
        data
        dayStep
        nightStep
        daynightStatus
    SMainHMIReadyStatus: category=STRUCTURE
      element status: implementation-data-type=UInt8
    SPowerExtendShutdownTime: category=STRUCTURE
      element domainId: implementation-data-type=EDomainId
      element timeoutMs: implementation-data-type=UInt32
    SPowerKeepSystemAwake: category=STRUCTURE
      element domainId: implementation-data-type=EDomainId
      element timeoutMs: implementation-data-type=UInt32
    SPowerSystemState: category=STRUCTURE
      element domainId: implementation-data-type=EDomainId
      element state: implementation-data-type=ESystemState
    SPowerSystemStateReqChange: category=STRUCTURE
      element state: implementation-data-type=ESystemState
      element domainId: implementation-data-type=EDomainId
    SRTT_Icon: category=STRUCTURE
      element icon: implementation-data-type=data_u8_2
    SRTT_Status: category=STRUCTURE
      element mask: implementation-data-type=data_u8_2
    SRTT_Toggle: category=STRUCTURE
      element positions: implementation-data-type=UInt8
      element display: implementation-data-type=UInt8
    SSafeHMIReadyStatus: category=STRUCTURE
      element status: implementation-data-type=UInt8
    SShiftInd: category=STRUCTURE
      6 x element, all with category=TYPE_REFERENCE, implementation-data-type=UInt8:
        Shift_Ind_Pos
        Shift_Ind_BlinkReq
        Shift_Ind_DisplayDecState
        Shift_Ind_Down
        Shift_Ind_Screen_ShiftType
        Shift_Ind_Up
    SShiftPosIndStatus: category=STRUCTURE
      element status: implementation-data-type=SShiftInd
    SSlowGuageInfo: category=STRUCTURE
      element gaugeInfo: implementation-data-type=SGaugeInfo
    STpmsWarningData: category=STRUCTURE
      element tpmsWarndata: implementation-data-type=data_u32_5
    STT_Status: category=STRUCTURE
      element mask: implementation-data-type=data_u8_15
    SUpdateLongServiceReq: category=STRUCTURE
      7 x element, all with category=TYPE_REFERENCE:
        msgId: implementation-data-type=UInt16
        msgSize: implementation-data-type=UInt16
        memoryType: implementation-data-type=UInt8
        memoryCmd: implementation-data-type=UInt8
        sid: implementation-data-type=UInt8
        length: implementation-data-type=UInt32
        data: implementation-data-type=data_u8_512
    SUpdateShortServiceReq: category=STRUCTURE
      7 x element, all with category=TYPE_REFERENCE:
        msgId: implementation-data-type=UInt16
        msgSize: implementation-data-type=UInt16
        memoryType: implementation-data-type=UInt8
        memoryCmd: implementation-data-type=UInt8
        sid: implementation-data-type=UInt8
        length: implementation-data-type=UInt32
        data: implementation-data-type=data_u8_64
    SUpdateShortServiceResp: category=STRUCTURE
      7 x element, all with category=TYPE_REFERENCE:
        msgId: implementation-data-type=UInt16
        msgSize: implementation-data-type=UInt16
        sid: implementation-data-type=UInt8
        length: implementation-data-type=UInt16
        responseCode: implementation-data-type=UInt8
        NRC: implementation-data-type=UInt8
        data: implementation-data-type=data_u8_64
    SWarningDisplay: category=STRUCTURE
      element show: implementation-data-type=UInt8
      element warningId: implementation-data-type=UInt16
      element dynData: implementation-data-type=data_u8_8
    SWarningDisplayAvailable: category=STRUCTURE
      element status: implementation-data-type=UInt8
    SWarningExtDisplay: category=STRUCTURE
      element show: implementation-data-type=UInt8
      element warningId: implementation-data-type=UInt16
      element dynData: implementation-data-type=data_u8_8
    SWarningStatus: category=STRUCTURE
      element visible: implementation-data-type=UInt8
      element warningId: implementation-data-type=UInt16
      element dynData: implementation-data-type=data_u8_10
  40 x sender receiver interface:
    DiagDIDRequest_Q: invalidation-policy{data-element=DiagDIDRequestData, handle-invalid=DONT-INVALIDATE}
      data DiagDIDRequestData: sw-impl-policy=QUEUED, type=SDiagDIDRequest
    DiagIOCtrlRequest_Q: invalidation-policy{data-element=DiagIOCtrlRequestData, handle-invalid=DONT-INVALIDATE}
      data DiagIOCtrlRequestData: sw-impl-policy=QUEUED, type=SDiagIOCtrlRequest
    DiagResponse_Q: invalidation-policy{data-element=DiagResponseData, handle-invalid=DONT-INVALIDATE}
      data DiagResponseData: sw-impl-policy=QUEUED, type=SDiagResponse
    DiagRoutineRequest_Q: invalidation-policy{data-element=DiagRoutineRequestData, handle-invalid=DONT-INVALIDATE}
      data DiagRoutineRequestData: sw-impl-policy=QUEUED, type=SDiagRoutineRequest
    DisplayCurrentState: invalidation-policy{data-element=DisplayCurrentStateData, handle-invalid=DONT-INVALIDATE}
      data DisplayCurrentStateData: type=SDisplayCurrentState
    DisplaySetPower: invalidation-policy{data-element=DisplaySetPowerData, handle-invalid=DONT-INVALIDATE}
      data DisplaySetPowerData: type=SDisplaySetPower
    EmmcErrorNotifier: invalidation-policy{data-element=EmmcErrorNotifierData, handle-invalid=DONT-INVALIDATE}
      data EmmcErrorNotifierData: type=SEmmcErrorNotifier
    FastGaugeInfo: invalidation-policy{data-element=FastGaugeInfoData, handle-invalid=DONT-INVALIDATE}
      data FastGaugeInfoData: type=SFastGaugeInfo
    FRTT_Status: invalidation-policy{data-element=FRTT_StatusData, handle-invalid=DONT-INVALIDATE}
      data FRTT_StatusData: type=SFRTT_Status
    HealthDomainFatalError_Q: invalidation-policy{data-element=HealthDomainFatalErrorData, handle-invalid=DONT-INVALIDATE}
      data HealthDomainFatalErrorData: sw-impl-policy=QUEUED, type=SHealthDomainFatalError
    HealthDomainHeartbeat_Q: invalidation-policy{data-element=HealthDomainHeartbeatData, handle-invalid=DONT-INVALIDATE}
      data HealthDomainHeartbeatData: sw-impl-policy=QUEUED, type=SHealthDomainHeartbeat
    HealthDumpData_Q: invalidation-policy{data-element=HealthDumpDataData, handle-invalid=DONT-INVALIDATE}
      data HealthDumpDataData: sw-impl-policy=QUEUED, type=SHealthDumpData
    HealthDumpGetData_Q: invalidation-policy{data-element=HealthDumpGetDataData, handle-invalid=DONT-INVALIDATE}
      data HealthDumpGetDataData: sw-impl-policy=QUEUED, type=SHealthDumpGetData
    HealthDumpGetHdr_Q: invalidation-policy{data-element=HealthDumpGetHdrData, handle-invalid=DONT-INVALIDATE}
      data HealthDumpGetHdrData: sw-impl-policy=QUEUED, type=SHealthDumpGetHdr
    HealthDumpHdrInfo_Q: invalidation-policy{data-element=HealthDumpHdrInfoData, handle-invalid=DONT-INVALIDATE}
      data HealthDumpHdrInfoData: sw-impl-policy=QUEUED, type=SHealthDumpHdrInfo
    HealthEventRecord_Q: invalidation-policy{data-element=HealthEventRecordData, handle-invalid=DONT-INVALIDATE}
      data HealthEventRecordData: sw-impl-policy=QUEUED, type=SHealthEventRecord
    HudWarningDisplay: invalidation-policy{data-element=HudWarningDisplayData, handle-invalid=DONT-INVALIDATE}
      data HudWarningDisplayData: type=SHudWarningDisplay
    HudWarningStatus: invalidation-policy{data-element=HudWarningStatusData, handle-invalid=DONT-INVALIDATE}
      data HudWarningStatusData: type=SHudWarningStatus
    IgnState_Q: invalidation-policy{data-element=IgnStateData, handle-invalid=DONT-INVALIDATE}
      data IgnStateData: sw-impl-policy=QUEUED, type=SIgnState
    IlluminationData: invalidation-policy{data-element=IlluminationDataData, handle-invalid=DONT-INVALIDATE}
      data IlluminationDataData: type=SIlluminationData
    MainHMIReadyStatus: invalidation-policy{data-element=MainHMIReadyStatusData, handle-invalid=DONT-INVALIDATE}
      data MainHMIReadyStatusData: sw-impl-policy=QUEUED, type=SMainHMIReadyStatus
    PowerExtendShutdownTime_Q: invalidation-policy{data-element=PowerExtendShutdownTimeData, handle-invalid=DONT-INVALIDATE}
      data PowerExtendShutdownTimeData: sw-impl-policy=QUEUED, type=SPowerExtendShutdownTime
    PowerKeepSystemAwake_Q: invalidation-policy{data-element=PowerKeepSystemAwakeData, handle-invalid=DONT-INVALIDATE}
      data PowerKeepSystemAwakeData: sw-impl-policy=QUEUED, type=SPowerKeepSystemAwake
    PowerSystemState: invalidation-policy{data-element=PowerSystemStateData, handle-invalid=DONT-INVALIDATE}
      data PowerSystemStateData: type=SPowerSystemState
    PowerSystemStateReqChange: invalidation-policy{data-element=PowerSystemStateReqChangeData, handle-invalid=DONT-INVALIDATE}
      data PowerSystemStateReqChangeData: type=SPowerSystemStateReqChange
    RTT_Icon: invalidation-policy{data-element=RTT_IconData, handle-invalid=DONT-INVALIDATE}
      data RTT_IconData: type=SRTT_Icon
    RTT_Status: invalidation-policy{data-element=RTT_StatusData, handle-invalid=DONT-INVALIDATE}
      data RTT_StatusData: type=SRTT_Status
    RTT_Toggle: invalidation-policy{data-element=RTT_ToggleData, handle-invalid=DONT-INVALIDATE}
      data RTT_ToggleData: type=SRTT_Toggle
    SafeHMIReadyStatus: invalidation-policy{data-element=SafeHMIReadyStatusData, handle-invalid=DONT-INVALIDATE}
      data SafeHMIReadyStatusData: sw-impl-policy=QUEUED, type=SSafeHMIReadyStatus
    ShiftPosIndStatus: invalidation-policy{data-element=ShiftPosIndStatusData, handle-invalid=DONT-INVALIDATE}
      data ShiftPosIndStatusData: type=SShiftPosIndStatus
    SlowGaugeInfo: invalidation-policy{data-element=SlowGaugeInfoData, handle-invalid=DONT-INVALIDATE}
      data SlowGaugeInfoData: type=SSlowGuageInfo
    TpmsWarningData: invalidation-policy{data-element=TpmsWarningDataData, handle-invalid=DONT-INVALIDATE}
      data TpmsWarningDataData: type=STpmsWarningData
    TT_Status: invalidation-policy{data-element=TT_StatusData, handle-invalid=DONT-INVALIDATE}
      data TT_StatusData: type=STT_Status
    UpdateLongServiceReq: invalidation-policy{data-element=UpdateLongServiceReqData, handle-invalid=DONT-INVALIDATE}
      data UpdateLongServiceReqData: sw-impl-policy=QUEUED, type=SUpdateLongServiceReq
    UpdateShortServiceReq: invalidation-policy{data-element=UpdateShortServiceReqData, handle-invalid=DONT-INVALIDATE}
      data UpdateShortServiceReqData: sw-impl-policy=QUEUED, type=SUpdateShortServiceReq
    UpdateShortServiceResp: invalidation-policy{data-element=UpdateShortServiceRespData, handle-invalid=DONT-INVALIDATE}
      data UpdateShortServiceRespData: sw-impl-policy=QUEUED, type=SUpdateShortServiceResp
    Warning_Status: invalidation-policy{data-element=WarningStatusData, handle-invalid=DONT-INVALIDATE}
      data WarningStatusData: type=SWarningStatus
    WarningDisplay: invalidation-policy{data-element=WarningDisplayData, handle-invalid=DONT-INVALIDATE}
      data WarningDisplayData: type=SWarningDisplay
    WarningDisplayAvailable: invalidation-policy{data-element=WarningDisplayAvailableData, handle-invalid=DONT-INVALIDATE}
      data WarningDisplayAvailableData: type=SWarningDisplayAvailable
    WarningExtDisplay: invalidation-policy{data-element=WarningExtDisplayData, handle-invalid=DONT-INVALIDATE}
      data WarningExtDisplayData: type=SWarningExtDisplay
package /E40_Platform_System_SystemPackage/Types/DataConstrs
  range SInt32_DataConstraint: raw -2147483648..2147483647
  range UInt16_DataConstraint: raw 0..65535
  range UInt32_DataConstraint: raw 0..4294967295
  range UInt8_DataConstraint: raw 0..255
